VERSION "dbc-export 1 2026.26.6.5"

NS_ :

BS_:

BU_: APP BMS CC CMP CMPD CP DAS DI DIF DIR EPBL EPBR EVSE FC GTW HCML HCMR HVP ICR PCS PCS2 PLG PM PMF PMR PTC SCCM SCM SCS SDCR TAS UMC V2G VC VCBATT VCBATT0 VCBATT1 VCBATT2 VCFRONT VCFRONT1 VCFRONT2 VCLEFT VCRIGHT VCSEAT2L VCSEAT2R VCSEC

BO_ 798 CP_alertMatrix: 8 CP
 SG_ CP_matrixIndex M : 0|4@1+ (1,0) [0|15] "" Vector__XXX
 SG_ CP_a001_canRx m0 : 4|1@1+ (1,0) [0|1] "" Vector__XXX
 SG_ CP_a002_canTx m0 : 5|1@1+ (1,0) [0|1] "" Vector__XXX
 SG_ CP_a003_canError m0 : 6|1@1+ (1,0) [0|1] "" Vector__XXX
 SG_ CP_a004_proximityRationality m0 : 7|1@1+ (1,0) [0|1] "" Vector__XXX
 SG_ CP_a005_gbdcLiveDisconnect m0 : 8|1@1+ (1,0) [0|1] "" Vector__XXX
 SG_ CP_a006_lostCommsBMS m0 : 9|1@1+ (1,0) [0|1] "" Vector__XXX
 SG_ CP_a007_watchdog m0 : 10|1@1+ (1,0) [0|1] "" Vector__XXX
 SG_ CP_a008_memoryError m0 : 11|1@1+ (1,0) [0|1] "" Vector__XXX
 SG_ CP_a009_coverOpenAllChgBlocked m0 : 12|1@1+ (1,0) [0|1] "" Vector__XXX
 SG_ CP_a010_pilotRationality m0 : 13|1@1+ (1,0) [0|1] "" Vector__XXX
 SG_ CP_a011_eeprom m0 : 14|1@1+ (1,0) [0|1] "" Vector__XXX
 SG_ CP_a012_ledDriver m0 : 15|1@1+ (1,0) [0|1] "" Vector__XXX
 SG_ CP_a013_lostCommsGTW m0 : 16|1@1+ (1,0) [0|1] "" Vector__XXX
 SG_ CP_a014_lostCommsCHG m0 : 17|1@1+ (1,0) [0|1] "" Vector__XXX
 SG_ CP_a015_apsVov m0 : 18|1@1+ (1,0) [0|1] "" Vector__XXX
 SG_ CP_a016_apsVuv m0 : 19|1@1+ (1,0) [0|1] "" Vector__XXX
 SG_ CP_a017_fiveVov m0 : 20|1@1+ (1,0) [0|1] "" Vector__XXX
 SG_ CP_a018_fiveVuv m0 : 21|1@1+ (1,0) [0|1] "" Vector__XXX
 SG_ CP_a019_threeVov m0 : 22|1@1+ (1,0) [0|1] "" Vector__XXX
 SG_ CP_a020_threeVuv m0 : 23|1@1+ (1,0) [0|1] "" Vector__XXX
 SG_ CP_a021_zeroVov m0 : 24|1@1+ (1,0) [0|1] "" Vector__XXX
 SG_ CP_a022_zeroVuv m0 : 25|1@1+ (1,0) [0|1] "" Vector__XXX
 SG_ CP_a023_gbdcSessionFailed m0 : 26|1@1+ (1,0) [0|1] "" Vector__XXX
 SG_ CP_a024_ledsUC m0 : 27|1@1+ (1,0) [0|1] "" Vector__XXX
 SG_ CP_a025_ledsOC m0 : 28|1@1+ (1,0) [0|1] "" Vector__XXX
 SG_ CP_a026_networkManagement m0 : 29|1@1+ (1,0) [0|1] "" Vector__XXX
 SG_ CP_a027_doorSensorOutOfSpec m0 : 30|1@1+ (1,0) [0|1] "" Vector__XXX
 SG_ CP_a028_insertEnableMismatch m0 : 31|1@1+ (1,0) [0|1] "" Vector__XXX
 SG_ CP_a029_doorClosedProxPilot m0 : 32|1@1+ (1,0) [0|1] "" Vector__XXX
 SG_ CP_a030_busOff m0 : 33|1@1+ (1,0) [0|1] "" Vector__XXX
 SG_ CP_a031_doorClosedCommandedOpen m0 : 34|1@1+ (1,0) [0|1] "" Vector__XXX
 SG_ CP_a032_doorOpenExpectedClosed m0 : 35|1@1+ (1,0) [0|1] "" Vector__XXX
 SG_ CP_a033_spiOpen m0 : 36|1@1+ (1,0) [0|1] "" Vector__XXX
 SG_ CP_a034_calibrationIncomplete m0 : 37|1@1+ (1,0) [0|1] "" Vector__XXX
 SG_ CP_a035_latchMovement_1 m0 : 38|1@1+ (1,0) [0|1] "" Vector__XXX
 SG_ CP_a036_latchNotDisengaged m0 : 39|1@1+ (1,0) [0|1] "" Vector__XXX
 SG_ CP_a037_latchNotEngaged m0 : 40|1@1+ (1,0) [0|1] "" Vector__XXX
 SG_ CP_a038_latchNotBlocking m0 : 41|1@1+ (1,0) [0|1] "" Vector__XXX
 SG_ CP_a039_latchMovement_2 m0 : 42|1@1+ (1,0) [0|1] "" Vector__XXX
 SG_ CP_a040_doNotUse m0 : 43|1@1+ (1,0) [0|1] "" Vector__XXX
 SG_ CP_a041_doorSensorUnplugged m0 : 44|1@1+ (1,0) [0|1] "" Vector__XXX
 SG_ CP_a042_doorAssemblyBroken m0 : 45|1@1+ (1,0) [0|1] "" Vector__XXX
 SG_ CP_a043_doorPotIrrational m0 : 46|1@1+ (1,0) [0|1] "" Vector__XXX
 SG_ CP_a044_lostCommsHVP m0 : 47|1@1+ (1,0) [0|1] "" Vector__XXX
 SG_ CP_a045_lostCommsVCSEC m0 : 48|1@1+ (1,0) [0|1] "" Vector__XXX
 SG_ CP_a046_lostCommsEVSE m0 : 49|1@1+ (1,0) [0|1] "" Vector__XXX
 SG_ CP_a047_lostCommsVCFRONT m0 : 50|1@1+ (1,0) [0|1] "" Vector__XXX
 SG_ CP_a048_lostCommsUI m0 : 51|1@1+ (1,0) [0|1] "" Vector__XXX
 SG_ CP_a049_multipleCablesDetected m0 : 52|1@1+ (1,0) [0|1] "" Vector__XXX
 SG_ CP_a050_latchNotConnected m0 : 53|1@1+ (1,0) [0|1] "" Vector__XXX
 SG_ CP_a051_doorInductiveSensorMIA m0 : 54|1@1+ (1,0) [0|1] "" Vector__XXX
 SG_ CP_a052_chademoNotSupported m0 : 55|1@1+ (1,0) [0|1] "" Vector__XXX
 SG_ CP_a053_proxLatchedNoPilot m0 : 56|1@1+ (1,0) [0|1] "" Vector__XXX
 SG_ CP_a054_cableNotSecured m0 : 57|1@1+ (1,0) [0|1] "" Vector__XXX
 SG_ CP_a055_chargeStoppedNoPilot m0 : 58|1@1+ (1,0) [0|1] "" Vector__XXX
 SG_ CP_a056_proxDisconnected m0 : 59|1@1+ (1,0) [0|1] "" Vector__XXX
 SG_ CP_a057_ccs1AdapterBtnPress m0 : 60|1@1+ (1,0) [0|1] "" Vector__XXX
 SG_ CP_a058_acChargeRetryPending m0 : 61|1@1+ (1,0) [0|1] "" Vector__XXX
 SG_ CP_a059_swcanError m0 : 62|1@1+ (1,0) [0|1] "" Vector__XXX
 SG_ CP_a060_lostCommsPCS m0 : 63|1@1+ (1,0) [0|1] "" Vector__XXX
 SG_ CP_a061_uhfReceiverMIA m1 : 4|1@1+ (1,0) [0|1] "" Vector__XXX
 SG_ CP_a062_scOutOfService m1 : 5|1@1+ (1,0) [0|1] "" Vector__XXX
 SG_ CP_a063_scUpdateInProgress m1 : 6|1@1+ (1,0) [0|1] "" Vector__XXX
 SG_ CP_a064_superchargingBlocked m1 : 7|1@1+ (1,0) [0|1] "" Vector__XXX
 SG_ CP_a065_selfTestFailed m1 : 8|1@1+ (1,0) [0|1] "" Vector__XXX
 SG_ CP_a066_proxLatchedIdlePilot m1 : 9|1@1+ (1,0) [0|1] "" Vector__XXX
 SG_ CP_a067_gbdcConnFault m1 : 10|1@1+ (1,0) [0|1] "" Vector__XXX
 SG_ CP_a068_doorSensorMismatch m1 : 11|1@1+ (1,0) [0|1] "" Vector__XXX
 SG_ CP_a069_doorInductiveSensorError m1 : 12|1@1+ (1,0) [0|1] "" Vector__XXX
 SG_ CP_a070_doorInductiveSensorReset m1 : 13|1@1+ (1,0) [0|1] "" Vector__XXX
 SG_ CP_a071_exiDecodeFailure m1 : 14|1@1+ (1,0) [0|1] "" Vector__XXX
 SG_ CP_a072_v2gEvccTimeout m1 : 15|1@1+ (1,0) [0|1] "" Vector__XXX
 SG_ CP_a073_iecComboShutdown m1 : 16|1@1+ (1,0) [0|1] "" Vector__XXX
 SG_ CP_a074_failedToEstablishV2gComm m1 : 17|1@1+ (1,0) [0|1] "" Vector__XXX
 SG_ CP_a075_v2gCommsFailure m1 : 18|1@1+ (1,0) [0|1] "" Vector__XXX
 SG_ CP_a076_LDC1612errorWatchdog m1 : 19|1@1+ (1,0) [0|1] "" Vector__XXX
 SG_ CP_a077_invalidMacAddress m1 : 20|1@1+ (1,0) [0|1] "" Vector__XXX
 SG_ CP_a078_latchNotDisengagedCold m1 : 21|1@1+ (1,0) [0|1] "" Vector__XXX
 SG_ CP_a079_cableNotSecuredCold m1 : 22|1@1+ (1,0) [0|1] "" Vector__XXX
 SG_ CP_a080_taskStackOverflow m1 : 23|1@1+ (1,0) [0|1] "" Vector__XXX
 SG_ CP_a081_swException m1 : 24|1@1+ (1,0) [0|1] "" Vector__XXX
 SG_ CP_a082_powerOnReset m1 : 25|1@1+ (1,0) [0|1] "" Vector__XXX
 SG_ CP_a083_watchdogTraceData m1 : 26|1@1+ (1,0) [0|1] "" Vector__XXX
 SG_ CP_a084_proxPeDisconnected_gb m1 : 27|1@1+ (1,0) [0|1] "" Vector__XXX
 SG_ CP_a085_dcPinTempFaulted m1 : 28|1@1+ (1,0) [0|1] "" Vector__XXX
 SG_ CP_a086_dcPinTempIrrational m1 : 29|1@1+ (1,0) [0|1] "" Vector__XXX
 SG_ CP_a087_dcTempModelFault m1 : 30|1@1+ (1,0) [0|1] "" Vector__XXX
 SG_ CP_a088_dcTempModelDeviation m1 : 31|1@1+ (1,0) [0|1] "" Vector__XXX
 SG_ CP_a089_plcConfigMismatch m1 : 32|1@1+ (1,0) [0|1] "" Vector__XXX
 SG_ CP_a090_ccsEvseLowIso m1 : 33|1@1+ (1,0) [0|1] "" Vector__XXX
 SG_ CP_a091_wrongSuperchargerHandle m1 : 34|1@1+ (1,0) [0|1] "" Vector__XXX
 SG_ CP_a092_modemAppLoadFailed m1 : 35|1@1+ (1,0) [0|1] "" Vector__XXX
 SG_ CP_a093_modemLoadedWithReset m1 : 36|1@1+ (1,0) [0|1] "" Vector__XXX
 SG_ CP_a094_inductiveResetSuccessful m1 : 37|1@1+ (1,0) [0|1] "" Vector__XXX
 SG_ CP_a095_thermalDcLimitActive m1 : 38|1@1+ (1,0) [0|1] "" Vector__XXX
 SG_ CP_a096_pilotWake m1 : 39|1@1+ (1,0) [0|1] "" Vector__XXX
 SG_ CP_a097_modeTransitionFailure m1 : 40|1@1+ (1,0) [0|1] "" Vector__XXX
 SG_ CP_a098_proximityWake m1 : 41|1@1+ (1,0) [0|1] "" Vector__XXX
 SG_ CP_a099_cableStateUnknown m1 : 42|1@1+ (1,0) [0|1] "" Vector__XXX
 SG_ CP_a100_inletHarnessIdIrrational m1 : 43|1@1+ (1,0) [0|1] "" Vector__XXX
 SG_ CP_a101_wcFoldbackActive m1 : 44|1@1+ (1,0) [0|1] "" Vector__XXX
 SG_ CP_a102_wcOvertempFault m1 : 45|1@1+ (1,0) [0|1] "" Vector__XXX
 SG_ CP_a103_proximityPeDisconnected m1 : 46|1@1+ (1,0) [0|1] "" Vector__XXX
 SG_ CP_a104_uhfResetSuccessful m1 : 47|1@1+ (1,0) [0|1] "" Vector__XXX
 SG_ CP_a105_hwUnableToSleep m1 : 48|1@1+ (1,0) [0|1] "" Vector__XXX
 SG_ CP_a106_uhfReceiverReset m1 : 49|1@1+ (1,0) [0|1] "" Vector__XXX
 SG_ CP_a107_chademoFoldbackActive m1 : 50|1@1+ (1,0) [0|1] "" Vector__XXX
 SG_ CP_a108_chademoOvertempFault m1 : 51|1@1+ (1,0) [0|1] "" Vector__XXX
 SG_ CP_a109_thermistorIrrational m1 : 52|1@1+ (1,0) [0|1] "" Vector__XXX
 SG_ CP_a110_thermalVelocityHigh m1 : 53|1@1+ (1,0) [0|1] "" Vector__XXX
 SG_ CP_a111_inletHeaterUnableToHeat m1 : 54|1@1+ (1,0) [0|1] "" Vector__XXX
 SG_ CP_a112_inletHeaterIrrationalTem m1 : 55|1@1+ (1,0) [0|1] "" Vector__XXX
 SG_ CP_a113_inletHeaterShortCircuit m1 : 56|1@1+ (1,0) [0|1] "" Vector__XXX
 SG_ CP_a114_ccsEvseFailed m1 : 57|1@1+ (1,0) [0|1] "" Vector__XXX
 SG_ CP_a115_unexpectedTcan1145State m1 : 58|1@1+ (1,0) [0|1] "" Vector__XXX
 SG_ CP_a116_misconfigurationDetected m1 : 59|1@1+ (1,0) [0|1] "" Vector__XXX
 SG_ CP_a117_inletHeaterUnableToRegul m1 : 60|1@1+ (1,0) [0|1] "" Vector__XXX
 SG_ CP_a118_iecComboLockUp m1 : 61|1@1+ (1,0) [0|1] "" Vector__XXX
 SG_ CP_a119_plcTransmitFailure m1 : 62|1@1+ (1,0) [0|1] "" Vector__XXX
 SG_ CP_a120_comboAdapterFoldback m1 : 63|1@1+ (1,0) [0|1] "" Vector__XXX
 SG_ CP_a121_PLCRLY_lostCommsCP m2 : 4|1@1+ (1,0) [0|1] "" Vector__XXX
 SG_ CP_a122_plcModemFailure m2 : 5|1@1+ (1,0) [0|1] "" Vector__XXX
 SG_ CP_a123_latchPotIrrational m2 : 6|1@1+ (1,0) [0|1] "" Vector__XXX
 SG_ CP_a124_ivledFault m2 : 7|1@1+ (1,0) [0|1] "" Vector__XXX
 SG_ CP_a125_unexpectedLVJuiceState m2 : 8|1@1+ (1,0) [0|1] "" Vector__XXX
 SG_ CP_a126_wakeOnUhfFault m2 : 9|1@1+ (1,0) [0|1] "" Vector__XXX
 SG_ CP_a127_lostCommsHVLINK m2 : 10|1@1+ (1,0) [0|1] "" Vector__XXX
 SG_ CP_a128_lostCommsVC m2 : 11|1@1+ (1,0) [0|1] "" Vector__XXX
 SG_ CP_a129_bldcDriverCommsFailed m2 : 12|1@1+ (1,0) [0|1] "" Vector__XXX
 SG_ CP_a130_bldcDriverCommsRecovered m2 : 13|1@1+ (1,0) [0|1] "" Vector__XXX
 SG_ CP_a131_evseCommTimeout m2 : 14|1@1+ (1,0) [0|1] "" Vector__XXX
 SG_ CP_a132_contractAuthTimeout m2 : 15|1@1+ (1,0) [0|1] "" Vector__XXX
 SG_ CP_a133_proxNeverLatched m2 : 16|1@1+ (1,0) [0|1] "" Vector__XXX
 SG_ CP_a134_plcModemNotExpected m2 : 17|1@1+ (1,0) [0|1] "" Vector__XXX
 SG_ CP_a135_sdpAttemptsFailed m2 : 18|1@1+ (1,0) [0|1] "" Vector__XXX
 SG_ CP_a136_sdpSideReqFailed m2 : 19|1@1+ (1,0) [0|1] "" Vector__XXX
 SG_ CP_a137_plcForwardError m2 : 20|1@1+ (1,0) [0|1] "" Vector__XXX
 SG_ CP_a138_swcanCommsAcEvseFaulted m2 : 21|1@1+ (1,0) [0|1] "" Vector__XXX
 SG_ CP_a139_pilotFaulted m2 : 22|1@1+ (1,0) [0|1] "" Vector__XXX
 SG_ CP_a140_superchargerFaulted m2 : 23|1@1+ (1,0) [0|1] "" Vector__XXX
 SG_ CP_a141_chademoAdapterFault m2 : 24|1@1+ (1,0) [0|1] "" Vector__XXX
 SG_ CP_a142_gbdcScConnFault m2 : 25|1@1+ (1,0) [0|1] "" Vector__XXX
 SG_ CP_a143_unsupportedChargeAdapter m2 : 26|1@1+ (1,0) [0|1] "" Vector__XXX
 SG_ CP_a144_nvmInitFailed m2 : 27|1@1+ (1,0) [0|1] "" Vector__XXX
 SG_ CP_a145_modemAppLoadFailedNA m2 : 28|1@1+ (1,0) [0|1] "" Vector__XXX
 SG_ CP_a146_ccsEvseMalfunction m2 : 29|1@1+ (1,0) [0|1] "" Vector__XXX
 SG_ CP_a147_inductiveRecoveredMia m2 : 30|1@1+ (1,0) [0|1] "" Vector__XXX
 SG_ CP_a148_bldcTachFeedbackMia m2 : 31|1@1+ (1,0) [0|1] "" Vector__XXX
 SG_ CP_a149_pilotPeriodInvalid m2 : 32|1@1+ (1,0) [0|1] "" Vector__XXX
 SG_ CP_a150_railToggleTimeout m2 : 33|1@1+ (1,0) [0|1] "" Vector__XXX
 SG_ CP_a151_badPilotDiodeDetected m2 : 34|1@1+ (1,0) [0|1] "" Vector__XXX
 SG_ CP_a152_pilotEdgeDetectionFailed m2 : 35|1@1+ (1,0) [0|1] "" Vector__XXX
 SG_ CP_a153_thermalAcLimitActive m2 : 36|1@1+ (1,0) [0|1] "" Vector__XXX
 SG_ CP_a154_acChargingStoppedOT m2 : 37|1@1+ (1,0) [0|1] "" Vector__XXX
 SG_ CP_a155_hallPresenceRationality m2 : 38|1@1+ (1,0) [0|1] "" Vector__XXX
 SG_ CP_a156_gbdcPrechargingConcern m2 : 39|1@1+ (1,0) [0|1] "" Vector__XXX
 SG_ CP_a157_doorOpenRateLimiter m2 : 40|1@1+ (1,0) [0|1] "" Vector__XXX
 SG_ CP_a158_doorCloseRateLimiter m2 : 41|1@1+ (1,0) [0|1] "" Vector__XXX
 SG_ CP_a159_swcanHealthCheckFailed m2 : 42|1@1+ (1,0) [0|1] "" Vector__XXX
 SG_ CP_a160_latchDisengageInDcCharge m2 : 43|1@1+ (1,0) [0|1] "" Vector__XXX
 SG_ CP_a161_badPilotDiodeDetectedCN m2 : 44|1@1+ (1,0) [0|1] "" Vector__XXX
 SG_ CP_a162_pilotEdgeDetectionFailed m2 : 45|1@1+ (1,0) [0|1] "" Vector__XXX
 SG_ CP_a163_coverOpenDcChgBlocked m2 : 46|1@1+ (1,0) [0|1] "" Vector__XXX
 SG_ CP_a164_latchRedisengageRequeste m2 : 47|1@1+ (1,0) [0|1] "" Vector__XXX
 SG_ CP_a165_proxWiggleDetected m2 : 48|1@1+ (1,0) [0|1] "" Vector__XXX
 SG_ CP_a166_faultLineMismatchDetecte m2 : 49|1@1+ (1,0) [0|1] "" Vector__XXX
 SG_ CP_a167_doorIdIrrational m2 : 50|1@1+ (1,0) [0|1] "" Vector__XXX
 SG_ CP_a168_pilotHSDFaulted m2 : 51|1@1+ (1,0) [0|1] "" Vector__XXX
 SG_ CP_a170_selfTestFailed2 m2 : 53|1@1+ (1,0) [0|1] "" Vector__XXX
 SG_ CP_a172_triggerOdin m2 : 55|1@1+ (1,0) [0|1] "" Vector__XXX
 SG_ CP_a173_coverOpenAcChgBlocked m2 : 56|1@1+ (1,0) [0|1] "" Vector__XXX
 SG_ CP_a174_fwdedMsgLoadWarning m2 : 57|1@1+ (1,0) [0|1] "" Vector__XXX
 SG_ CP_a175_fwdedMsgDropped m2 : 58|1@1+ (1,0) [0|1] "" Vector__XXX
 SG_ CP_a176_lostCommsV2l m2 : 59|1@1+ (1,0) [0|1] "" Vector__XXX
 SG_ CP_a177_incompatibleV2lDeviceDet m2 : 60|1@1+ (1,0) [0|1] "" Vector__XXX
 SG_ CP_a178_v2xPlcCommsFault m2 : 61|1@1+ (1,0) [0|1] "" Vector__XXX
 SG_ CP_a179_evseCommsTlsError m2 : 62|1@1+ (1,0) [0|1] "" Vector__XXX
 SG_ CP_a182_pncdCommsError m3 : 5|1@1+ (1,0) [0|1] "" Vector__XXX
 SG_ CP_a183_certManagerError m3 : 6|1@1+ (1,0) [0|1] "" Vector__XXX
 SG_ CP_a184_certChangeEvent m3 : 7|1@1+ (1,0) [0|1] "" Vector__XXX
 SG_ CP_a185_pncAuthRejection m3 : 8|1@1+ (1,0) [0|1] "" Vector__XXX
 SG_ CP_a186_spiDmaFailure m3 : 9|1@1+ (1,0) [0|1] "" Vector__XXX
 SG_ CP_a187_highStackUsage m3 : 10|1@1+ (1,0) [0|1] "" Vector__XXX
 SG_ CP_a188_v2lEvseRequiresUpdate m3 : 11|1@1+ (1,0) [0|1] "" Vector__XXX
 SG_ CP_a189_resistivePresenceRationa m3 : 12|1@1+ (1,0) [0|1] "" Vector__XXX
 SG_ CP_d190_backCoverCircuitIssue m3 : 13|1@1+ (1,0) [0|1] "" Vector__XXX
 SG_ CP_d191_latchConnectionIssue m3 : 14|1@1+ (1,0) [0|1] "" Vector__XXX
 SG_ CP_d192_couplerTempHigh m3 : 15|1@1+ (1,0) [0|1] "" Vector__XXX
 SG_ CP_d193_proximityCircuitErratic m3 : 16|1@1+ (1,0) [0|1] "" Vector__XXX
 SG_ CP_d194_proximityCircuitRangeIss m3 : 17|1@1+ (1,0) [0|1] "" Vector__XXX
 SG_ CP_d195_couplerLockActuatorIssue m3 : 18|1@1+ (1,0) [0|1] "" Vector__XXX
 SG_ CP_d196_doorActuatorPerformanceI m3 : 19|1@1+ (1,0) [0|1] "" Vector__XXX
 SG_ CP_d197_doorSensorCircuitErratic m3 : 20|1@1+ (1,0) [0|1] "" Vector__XXX
 SG_ CP_d198_couplerTempSensorCircuit m3 : 21|1@1+ (1,0) [0|1] "" Vector__XXX
 SG_ CP_d199_hardwareConfigMismatch m3 : 22|1@1+ (1,0) [0|1] "" Vector__XXX
 SG_ CP_d200_pilotCircuitIssue m3 : 23|1@1+ (1,0) [0|1] "" Vector__XXX
 SG_ CP_a201_uhfDoorOpenRepeatedlyOve m3 : 24|1@1+ (1,0) [0|1] "" Vector__XXX
 SG_ CP_a202_failedToEstablishV2gComm m3 : 25|1@1+ (1,0) [0|1] "" Vector__XXX
 SG_ CP_a203_evseCommTimeout2 m3 : 26|1@1+ (1,0) [0|1] "" Vector__XXX
 SG_ CP_a204_sdpAttemptsFailed2 m3 : 27|1@1+ (1,0) [0|1] "" Vector__XXX
 SG_ CP_a205_doorPositionUndetectable m3 : 28|1@1+ (1,0) [0|1] "" Vector__XXX
 SG_ CP_a206_peToChassisDisconnected m3 : 29|1@1+ (1,0) [0|1] "" Vector__XXX
 SG_ CP_a207_v2xAuthenticationFailed m3 : 30|1@1+ (1,0) [0|1] "" Vector__XXX
 SG_ CP_a208_eipmCommsError m3 : 31|1@1+ (1,0) [0|1] "" Vector__XXX
 SG_ CP_a209_macphyFault m3 : 32|1@1+ (1,0) [0|1] "" Vector__XXX
 SG_ CP_a210_lostCommsPCSR m3 : 33|1@1+ (1,0) [0|1] "" Vector__XXX
 SG_ CP_a211_lostCommsPCSL m3 : 34|1@1+ (1,0) [0|1] "" Vector__XXX
 SG_ CP_a212_mcsPacketDrops m3 : 35|1@1+ (1,0) [0|1] "" Vector__XXX
 SG_ CP_a213_mcsTcpRetransmitStorm m3 : 36|1@1+ (1,0) [0|1] "" Vector__XXX
 SG_ CP_a214_mcsEthDriverRetransmitFa m3 : 37|1@1+ (1,0) [0|1] "" Vector__XXX
 SG_ CP_a215_mcsMacPhyErrors m3 : 38|1@1+ (1,0) [0|1] "" Vector__XXX
 SG_ CP_a216_mcsLinkLoss m3 : 39|1@1+ (1,0) [0|1] "" Vector__XXX
 SG_ CP_a217_teslaV2gCommsFailure m3 : 40|1@1+ (1,0) [0|1] "" Vector__XXX
 SG_ CP_a218_v2gCommsFailure2 m3 : 41|1@1+ (1,0) [0|1] "" Vector__XXX
 SG_ CP_a219_doorOpenInDrive m3 : 42|1@1+ (1,0) [0|1] "" Vector__XXX
 SG_ CP_a220_mcsChargingInterrupted m3 : 43|1@1+ (1,0) [0|1] "" Vector__XXX
 SG_ CP_a221_evseStartupTimeout m3 : 44|1@1+ (1,0) [0|1] "" Vector__XXX

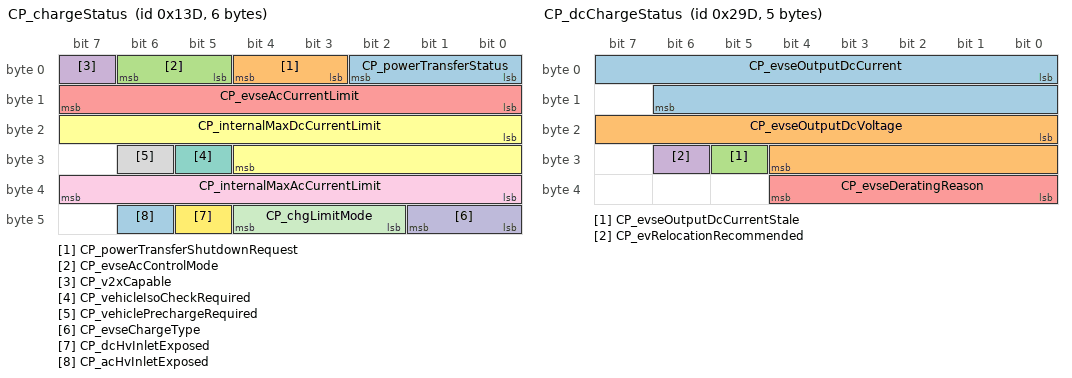
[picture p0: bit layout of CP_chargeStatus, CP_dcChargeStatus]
BO_ 317 CP_chargeStatus: 6 CP
 SG_ CP_powerTransferStatus : 0|3@1+ (1,0) [0|7] "" Vector__XXX
 SG_ CP_powerTransferShutdownRequest : 3|2@1+ (1,0) [0|3] "" Vector__XXX
 SG_ CP_evseAcControlMode : 5|2@1+ (1,0) [0|3] "" Vector__XXX
 SG_ CP_v2xCapable : 7|1@1+ (1,0) [0|1] "" Vector__XXX
 SG_ CP_evseAcCurrentLimit : 8|8@1+ (0.5,0) [0|127.5] "A" Vector__XXX
 SG_ CP_internalMaxDcCurrentLimit : 16|13@1+ (0.25,0) [0|2047.75] "A" Vector__XXX
 SG_ CP_vehicleIsoCheckRequired : 29|1@1+ (1,0) [0|1] "" Vector__XXX
 SG_ CP_vehiclePrechargeRequired : 30|1@1+ (1,0) [0|1] "" Vector__XXX
 SG_ CP_internalMaxAcCurrentLimit : 32|8@1+ (0.5,0) [0|127.5] "A" Vector__XXX
 SG_ CP_evseChargeType : 40|2@1+ (1,0) [0|3] "" Vector__XXX
 SG_ CP_chgLimitMode : 42|3@1+ (1,0) [0|7] "" Vector__XXX
 SG_ CP_dcHvInletExposed : 45|1@1+ (1,0) [0|1] "" Vector__XXX
 SG_ CP_acHvInletExposed : 46|1@1+ (1,0) [0|1] "" Vector__XXX

BO_ 669 CP_dcChargeStatus: 5 CP
 SG_ CP_evseOutputDcCurrent : 0|15@1- (0.125,0) [-2048|2047.875] "A" Vector__XXX
 SG_ CP_evseOutputDcVoltage : 16|13@1+ (0.07324219,0) [0|599.92675822] "V" Vector__XXX
 SG_ CP_evseOutputDcCurrentStale : 29|1@1+ (1,0) [0|1] "" Vector__XXX
 SG_ CP_evRelocationRecommended : 30|1@1+ (1,0) [0|1] "" Vector__XXX
 SG_ CP_evseDeratingReason : 32|5@1+ (1,0) [0|31] "" Vector__XXX

BO_ 541 CP_evseStatus: 8 CP
 SG_ CP_evseAccept : 0|1@1+ (1,0) [0|1] "" Vector__XXX
 SG_ CP_evseRequest : 1|1@1+ (1,0) [0|1] "" Vector__XXX
 SG_ CP_proximity : 2|2@1+ (1,0) [1|3] "" Vector__XXX
 SG_ CP_pilot : 4|3@1+ (1,0) [0|6] "" Vector__XXX
 SG_ CP_digitalCommsEstablished : 7|1@1+ (1,0) [0|1] "" Vector__XXX
 SG_ CP_pilotCurrent : 8|8@1+ (0.5,0) [0|127.5] "A" Vector__XXX
 SG_ CP_cableType : 16|3@1+ (1,0) [0|7] "" Vector__XXX
 SG_ CP_iecPilotState : 19|4@1+ (1,0) [0|15] "" Vector__XXX
 SG_ CP_plcSupported : 23|1@1+ (1,0) [0|1] "" Vector__XXX
 SG_ CP_cableCurrentLimit : 24|7@1+ (1,0) [0|127] "A" Vector__XXX
 SG_ CP_teslaSwcanState : 34|4@1+ (1,0) [0|15] "" Vector__XXX
 SG_ CP_evseChargeType_UI : 38|2@1+ (1,0) [0|3] "" Vector__XXX
 SG_ CP_gbState : 40|4@1+ (1,0) [0|15] "" Vector__XXX
 SG_ CP_gbdcStopChargeReason : 44|4@1+ (1,0) [0|15] "" Vector__XXX
 SG_ CP_gbdcFailureReason : 48|2@1+ (1,0) [0|3] "" Vector__XXX
 SG_ CP_gbdcChargeAttempts : 50|2@1+ (1,0) [0|3] "" Vector__XXX
 SG_ CP_acChargeState : 52|3@1+ (1,0) [0|7] "" Vector__XXX
 SG_ CP_acChargeType : 56|2@1+ (1,0) [0|3] "" Vector__XXX
 SG_ CP_teslaDcState : 58|4@1+ (1,0) [0|15] "" Vector__XXX

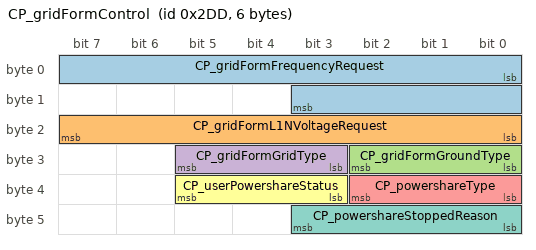
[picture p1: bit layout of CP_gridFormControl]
BO_ 733 CP_gridFormControl: 6 CP
 SG_ CP_gridFormFrequencyRequest : 0|12@1+ (0.01,40) [40|80.94] "Hz" Vector__XXX
 SG_ CP_gridFormL1NVoltageRequest : 16|8@1+ (1,40) [40|294] "V" Vector__XXX
 SG_ CP_gridFormGroundType : 24|3@1+ (1,0) [1|7] "" Vector__XXX
 SG_ CP_gridFormGridType : 27|3@1+ (1,0) [1|7] "" Vector__XXX
 SG_ CP_powershareType : 32|3@1+ (1,0) [0|7] "" Vector__XXX
 SG_ CP_userPowershareStatus : 35|3@1+ (1,0) [0|7] "" Vector__XXX
 SG_ CP_powershareStoppedReason : 40|4@1+ (1,0) [0|15] "" Vector__XXX

BO_ 1342 CP_info: 8 CP
 SG_ CP_infoIndex M : 0|8@1+ (1,0) [0|255] "" Vector__XXX
 SG_ CP_buildType m10 : 8|3@1+ (1,0) [0|7] "" Vector__XXX
 SG_ CP_buildConfigId m10 : 16|16@1+ (1,0) [0|65535] "" Vector__XXX
 SG_ CP_hardwareId m10 : 32|16@1+ (1,0) [0|65535] "" Vector__XXX
 SG_ CP_componentId m10 : 48|16@1+ (1,0) [0|65535] "" Vector__XXX
 SG_ CP_pcbaId m11 : 16|8@1+ (1,0) [0|255] "" Vector__XXX
 SG_ CP_assemblyId m11 : 24|8@1+ (1,0) [0|255] "" Vector__XXX
 SG_ CP_usageId m11 : 32|16@1+ (1,0) [0|65535] "" Vector__XXX
 SG_ CP_subUsageId m11 : 48|16@1+ (1,0) [0|65535] "" Vector__XXX
 SG_ CP_platformType m13 : 8|8@1+ (1,0) [0|255] "" Vector__XXX
 SG_ CP_appCrc m13 : 32|32@1+ (1,0) [0|4294967295] "" Vector__XXX
 SG_ CP_appGitHash m17 : 8|56@1+ (1,0) [0|7.20575940379e+16] "" Vector__XXX
 SG_ CP_bootGitHash m18 : 8|56@1+ (1,0) [0|7.20575940379e+16] "" Vector__XXX
 SG_ CP_bootUdsProtoVersion m20 : 8|8@1+ (1,0) [0|255] "" Vector__XXX
 SG_ CP_bootCrc m20 : 32|32@1+ (1,0) [0|4294967295] "" Vector__XXX

BO_ 1885 CP_loggingFast: 8 CP
 SG_ CP_loggingFastSelect M : 0|4@1+ (1,0) [0|15] "" Vector__XXX
 SG_ CP_inductiveSensor_raw m0 : 4|28@1+ (1,0) [0|268435455] "" Vector__XXX
 SG_ CP_doorOpenActuationTime m0 : 32|14@1+ (1,0) [0|16383] "ms" Vector__XXX
 SG_ CP_doorCloseActuationTime m0 : 46|14@1+ (1,0) [0|16383] "ms" Vector__XXX
 SG_ CP_chargeCableSecured m0 : 60|1@1+ (1,0) [0|1] "" Vector__XXX
 SG_ CP_chargeCablePresent m0 : 61|1@1+ (1,0) [0|1] "" Vector__XXX
 SG_ CP_latchCheckAvailable m0 : 62|1@1+ (1,0) [0|1] "" Vector__XXX
 SG_ CP_UHF_controlState m2 : 4|4@1+ (1,0) [0|15] "" Vector__XXX
 SG_ CP_proximityV m2 : 8|16@1+ (0.0001,0) [0|6.5535] "V" Vector__XXX
 SG_ CP_proximityV_GBCC1 m2 : 24|14@1+ (0.001,0) [0|13.3] "V" Vector__XXX
 SG_ CP_proximityV_GBCC2 m2 : 38|14@1+ (0.001,0) [0|13.3] "V" Vector__XXX
 SG_ CP_doorPot m2 : 52|12@1+ (0.025,0) [0|100] "%" Vector__XXX
 SG_ CP_doorPresenceSensorV m3 : 4|12@1+ (0.001221,0) [0|4.999995] "V" Vector__XXX
 SG_ CP_doorOpenRequest m3 : 16|4@1+ (1,0) [0|15] "" Vector__XXX
 SG_ CP_doorOpenEndOfDriveReason m3 : 20|3@1+ (1,0) [0|7] "" Vector__XXX
 SG_ CP_coverClosed m3 : 23|1@1+ (1,0) [0|1] "" Vector__XXX
 SG_ CP_doorCloseEndOfDriveReason m3 : 24|3@1+ (1,0) [0|7] "" Vector__XXX
 SG_ CP_doorCloseRequest m3 : 27|5@1+ (1,0) [0|31] "" Vector__XXX
 SG_ CP_latchDisengagingTime m3 : 32|10@1+ (1,0) [0|1023] "ms" Vector__XXX
 SG_ CP_latchEngagingTime m3 : 42|10@1+ (1,0) [0|1023] "ms" Vector__XXX
 SG_ CP_latchDisengagingStopReason m3 : 52|3@1+ (1,0) [0|7] "" Vector__XXX
 SG_ CP_latchEngagingStopReason m3 : 55|3@1+ (1,0) [0|7] "" Vector__XXX
 SG_ CP_pilotUnlatchRequestActive m3 : 58|1@1+ (1,0) [0|1] "" Vector__XXX
 SG_ CP_doorIdDetectionState m3 : 59|2@1+ (1,0) [1|3] "" Vector__XXX
 SG_ CP_doorIdDetectedBin m3 : 61|2@1+ (1,0) [0|3] "" Vector__XXX
 SG_ CP_semiV2LatchNonLinear m3 : 63|1@1+ (1,0) [0|1] "" Vector__XXX

BO_ 989 CP_loggingSlow: 8 CP
 SG_ CP_loggingSlowSelect M : 0|4@1+ (1,0) [0|15] "" Vector__XXX
 SG_ CP_UHF_chipState m3 : 4|3@1+ (1,0) [0|7] "" Vector__XXX
 SG_ CP_UHF_rssi m3 : 8|8@1+ (1,0) [0|255] "" Vector__XXX
 SG_ CP_UHF_rxOverflow m3 : 16|1@1+ (1,0) [0|1] "" Vector__XXX
 SG_ CP_UHF_rxNumBytes m3 : 17|8@1+ (1,0) [0|255] "" Vector__XXX
 SG_ CP_UHF_selfTestRssi m3 : 25|8@1+ (1,0) [0|255] "" Vector__XXX
 SG_ CP_latchI m3 : 33|12@1+ (0.0025,0) [0|10.2375] "A" Vector__XXX
 SG_ CP_inlet1HarnessIdState m3 : 45|2@1+ (1,0) [1|3] "" Vector__XXX
 SG_ CP_inlet1HarnessIdValue m3 : 47|3@1+ (1,0) [0|7] "" Vector__XXX
 SG_ CP_inlet2HarnessIdState m3 : 50|2@1+ (1,0) [1|3] "" Vector__XXX
 SG_ CP_inlet2HarnessIdValue m3 : 52|3@1+ (1,0) [0|7] "" Vector__XXX
 SG_ CP_inletHeaterState m3 : 55|2@1+ (1,0) [0|3] "" Vector__XXX
 SG_ CP_inletHeaterDuty m3 : 57|7@1+ (1,0) [0|100] "%" Vector__XXX
 SG_ CP_5vSwV m4 : 4|8@1+ (0.02745098,0) [0|6.9999999] "V" Vector__XXX
 SG_ CP_boardTemperature m4 : 12|8@1+ (1.29411768913,-50) [-50|280] "C" Vector__XXX
 SG_ CP_refVoltage m4 : 20|8@1+ (0.0070588234812,0) [0|1.79999998771] "V" Vector__XXX
 SG_ CP_doorId_intervalMin10s m4 : 28|8@1+ (0.0196078438312,0) [0|5] "V" Vector__XXX
 SG_ CP_doorId_intervalMax10s m4 : 36|8@1+ (0.0196078438312,0) [0|5] "V" Vector__XXX
 SG_ CP_wakeOnPushCounter m4 : 60|3@1+ (1,0) [0|7] "" Vector__XXX
 SG_ CP_doorPushLockoutActive m4 : 63|1@1+ (1,0) [0|1] "" Vector__XXX
 SG_ CP_nvm_dataValid m5 : 4|1@1+ (1,0) [0|1] "" Vector__XXX
 SG_ CP_nvm_doorOpenCycles m5 : 5|16@1+ (1,0) [0|65535] "" Vector__XXX
 SG_ CP_nvm_doorCloseCycles m5 : 21|16@1+ (1,0) [0|65535] "" Vector__XXX
 SG_ CP_nvm_doorOpen m5 : 37|1@1+ (1,0) [0|1] "" Vector__XXX
 SG_ CP_nvm_doorPresent m5 : 38|1@1+ (1,0) [0|1] "" Vector__XXX
 SG_ CP_nvm_doorPresentValid m5 : 39|1@1+ (1,0) [0|1] "" Vector__XXX
 SG_ CP_nvm_badPilotDiodeDetected m5 : 40|1@1+ (1,0) [0|1] "" Vector__XXX
 SG_ CP_nvm_pilotDiodeFaultCount m5 : 41|3@1+ (1,0) [0|7] "" Vector__XXX
 SG_ CP_doorOpenLimiterMaxCount m5 : 44|4@1+ (1,0) [0|15] "counts" Vector__XXX
 SG_ CP_doorOpenLimiterMaxRequestType m5 : 48|4@1+ (1,0) [0|15] "" Vector__XXX
 SG_ CP_doorCloseLimiterMaxCount m5 : 52|4@1+ (1,0) [0|15] "counts" Vector__XXX
 SG_ CP_doorCloseLimiterMaxRequestTyp m5 : 56|5@1+ (1,0) [0|31] "" Vector__XXX
 SG_ CP_proximityWakeCounter m5 : 61|3@1+ (1,0) [0|7] "" Vector__XXX

BO_ 605 CP_status: 8 CP
 SG_ CP_type : 0|2@1+ (1,0) [0|3] "" Vector__XXX
 SG_ CP_insertEnableLine : 2|1@1+ (1,0) [0|1] "" Vector__XXX
 SG_ CP_latchState : 3|2@1+ (1,0) [1|3] "" Vector__XXX
 SG_ CP_permanentPowerRequest : 5|1@1+ (1,0) [0|1] "" Vector__XXX
 SG_ CP_chargeDoorOpen : 6|1@1+ (1,0) [0|1] "" Vector__XXX
 SG_ CP_doorControlState : 8|3@1+ (1,0) [0|7] "" Vector__XXX
 SG_ CP_doorButtonPressed : 11|1@1+ (1,0) [0|1] "" Vector__XXX
 SG_ CP_swcanRelayClosed : 12|1@1+ (1,0) [0|1] "" Vector__XXX
 SG_ CP_inhibitOta : 13|1@1+ (1,0) [0|1] "" Vector__XXX
 SG_ CP_chargeCableState : 14|2@1+ (1,0) [1|3] "" Vector__XXX
 SG_ CP_latchControlState : 16|3@1+ (1,0) [0|7] "" Vector__XXX
 SG_ CP_ledColor : 19|4@1+ (1,0) [0|15] "" Vector__XXX
 SG_ CP_UHF_handleFound : 23|1@1+ (1,0) [0|1] "" Vector__XXX
 SG_ CP_faultLineSensed : 24|1@1+ (1,0) [0|1] "" Vector__XXX
 SG_ CP_doorPresenceState : 25|3@1+ (1,0) [0|7] "" Vector__XXX
 SG_ CP_inductiveSensorState : 28|3@1+ (1,0) [0|7] "" Vector__XXX
 SG_ CP_chargeDoorOpenUI : 31|1@1+ (1,0) [0|1] "" Vector__XXX
 SG_ CP_vehicleUnlockRequest : 32|1@1+ (1,0) [0|1] "" Vector__XXX
 SG_ CP_coldWeatherMode : 33|1@1+ (1,0) [0|1] "" Vector__XXX
 SG_ CP_latchEngaged : 34|1@1+ (1,0) [0|1] "" Vector__XXX
 SG_ CP_inletHeaterUiState : 37|3@1+ (1,0) [0|7] "" Vector__XXX
 SG_ CP_userEvseModelType : 40|4@1+ (1,0) [0|15] "" Vector__XXX
 SG_ CP_evseGridFormHardwareType : 44|4@1+ (1,0) [0|14] "" Vector__XXX
 SG_ CP_faultLineV : 48|10@1+ (0.00455057667568,0) [0|4.65523993922] "V" Vector__XXX
 SG_ CP_faultLineSetByCP : 58|1@1+ (1,0) [0|1] "" Vector__XXX
 SG_ CP_AuthManagerState : 59|4@1+ (1,0) [0|15] "" Vector__XXX

BO_ 893 CP_thermalStatus: 8 CP
 SG_ CP_thermalStatusSelect M : 0|1@1+ (1,0) [0|1] "" Vector__XXX
 SG_ CP_pinTemperature1 m1 : 8|8@1+ (0.8039216,-55) [-55|149.99] "C" Vector__XXX
 SG_ CP_pinTemperature2 m1 : 16|8@1+ (0.8039216,-55) [-55|149.99] "C" Vector__XXX
 SG_ CP_pinTemperature3 m1 : 24|8@1+ (0.8039216,-55) [-55|149.99] "C" Vector__XXX
 SG_ CP_pinTemperature4 m1 : 32|8@1+ (0.8039216,-55) [-55|149.99] "C" Vector__XXX
 SG_ CP_pinTemp4Velocity m1 : 40|10@1- (0.15748,0) [-80.47228|80.3148] "C/min" Vector__XXX

BO_ 1566 CP_udsResponse: 8 CP
 SG_ CP_udsResponseData : 7|64@0+ (1,0) [0|1.84467440737e+19] "" Vector__XXX

BO_ 1001 DAS_bodyControls: 8 DAS
 SG_ DAS_headlightRequest : 0|2@1+ (1,0) [0|3] "" Vector__XXX
 SG_ DAS_hazardLightRequest : 2|2@1+ (1,0) [0|2] "" Vector__XXX
 SG_ DAS_wiperSpeed : 4|4@1+ (1,0) [0|15] "" Vector__XXX
 SG_ DAS_turnIndicatorRequest : 8|3@1+ (1,0) [0|7] "" Vector__XXX
 SG_ DAS_highLowBeamDecision : 11|2@1+ (1,0) [0|2] "" Vector__XXX
 SG_ DAS_heaterRequest : 13|2@1+ (1,0) [1|3] "" Vector__XXX
 SG_ DAS_highLowBeamOffReason : 15|3@1+ (1,0) [0|7] "" Vector__XXX
 SG_ DAS_forwardCamHeaterDutyCycle : 18|4@1+ (0.06666667,0) [0|1] "-" Vector__XXX
 SG_ DAS_dynamicBrakeLightRequest : 22|1@1+ (1,0) [0|1] "" Vector__XXX
 SG_ DAS_radarHeaterRequest : 23|1@1+ (1,0) [0|1] "" Vector__XXX
 SG_ DAS_ahlbOverride : 24|1@1+ (1,0) [0|1] "" Vector__XXX
 SG_ DAS_mirrorFoldRequest : 25|2@1+ (1,0) [0|2] "" Vector__XXX
 SG_ DAS_wiperWashRequest : 27|1@1+ (1,0) [0|1] "" Vector__XXX
 SG_ DAS_ulcConfirmationRequestActive : 28|1@1+ (1,0) [0|1] "" Vector__XXX
 SG_ DAS_overrideWiperSetting : 29|1@1+ (1,0) [0|1] "" Vector__XXX
 SG_ DAS_autoWiperState : 30|3@1+ (1,0) [0|7] "" Vector__XXX
 SG_ DAS_turnIndicatorRequestReason : 33|5@1+ (1,0) [0|31] "" Vector__XXX
 SG_ DAS_forwardRadarPowerRequest : 38|1@1+ (1,0) [0|1] "" Vector__XXX
 SG_ DAS_driverDomeLightRequest : 39|1@1+ (1,0) [0|1] "" Vector__XXX
 SG_ DAS_drivePowerStateRequest : 43|1@1+ (1,0) [0|1] "" Vector__XXX
 SG_ DAS_enableIcrDataCollection : 44|1@1+ (1,0) [0|1] "" Vector__XXX
 SG_ DAS_rPillarCamHeaterDutyCycle : 45|4@1+ (0.06666667,0) [0|1] "-" Vector__XXX
 SG_ DAS_adaptiveHighBeamIsFaulted : 49|1@1+ (1,0) [0|1] "" Vector__XXX
 SG_ DAS_restrictDoorReleaseLeft : 50|1@1+ (1,0) [0|1] "" Vector__XXX
 SG_ DAS_restrictDoorReleaseRight : 51|1@1+ (1,0) [0|1] "" Vector__XXX
 SG_ DAS_bodyControlsCounter : 52|4@1+ (1,0) [0|15] "" Vector__XXX
 SG_ DAS_bodyControlsChecksum : 56|8@1+ (1,0) [0|255] "" Vector__XXX

BO_TX_BU_ 798 : CP;
BO_TX_BU_ 317 : CP;
BO_TX_BU_ 669 : CP;
BO_TX_BU_ 541 : CP;
BO_TX_BU_ 733 : CP;
BO_TX_BU_ 1342 : CP;
BO_TX_BU_ 1885 : CP;
BO_TX_BU_ 989 : CP;
BO_TX_BU_ 605 : CP;
BO_TX_BU_ 893 : CP;
BO_TX_BU_ 1566 : CP;
BO_TX_BU_ 1001 : DAS;
CM_ BO_ 798 "Charge port controller message: alert matrix; frame length from the layout, not yet observed on a vehicle bus";
CM_ SG_ 798 CP_matrixIndex "Charge port controller: matrix index";
CM_ SG_ 798 CP_a001_canRx "Charge port controller: a001 can rx";
CM_ SG_ 798 CP_a002_canTx "Charge port controller: a002 can tx";
CM_ SG_ 798 CP_a003_canError "Charge port controller: a003 can error";
CM_ SG_ 798 CP_a004_proximityRationality "Charge port controller: a004 proximity rationality";
CM_ SG_ 798 CP_a005_gbdcLiveDisconnect "Charge port controller: a005 gbdc live disconnect";
CM_ SG_ 798 CP_a006_lostCommsBMS "Charge port controller: a006 lost comms BMS";
CM_ SG_ 798 CP_a007_watchdog "Charge port controller: a007 watchdog";
CM_ SG_ 798 CP_a008_memoryError "Charge port controller: a008 memory error";
CM_ SG_ 798 CP_a009_coverOpenAllChgBlocked "Charge port controller: a009 cover open all chg blocked";
CM_ SG_ 798 CP_a010_pilotRationality "Charge port controller: a010 pilot rationality";
CM_ SG_ 798 CP_a011_eeprom "Charge port controller: a011 eeprom";
CM_ SG_ 798 CP_a012_ledDriver "Charge port controller: a012 led driver";
CM_ SG_ 798 CP_a013_lostCommsGTW "Charge port controller: a013 lost comms GTW";
CM_ SG_ 798 CP_a014_lostCommsCHG "Charge port controller: a014 lost comms CHG";
CM_ SG_ 798 CP_a015_apsVov "Charge port controller: a015 aps vov";
CM_ SG_ 798 CP_a016_apsVuv "Charge port controller: a016 aps vuv";
CM_ SG_ 798 CP_a017_fiveVov "Charge port controller: a017 five vov";
CM_ SG_ 798 CP_a018_fiveVuv "Charge port controller: a018 five vuv";
CM_ SG_ 798 CP_a019_threeVov "Charge port controller: a019 three vov";
CM_ SG_ 798 CP_a020_threeVuv "Charge port controller: a020 three vuv";
CM_ SG_ 798 CP_a021_zeroVov "Charge port controller: a021 zero vov";
CM_ SG_ 798 CP_a022_zeroVuv "Charge port controller: a022 zero vuv";
CM_ SG_ 798 CP_a023_gbdcSessionFailed "Charge port controller: a023 gbdc session failed";
CM_ SG_ 798 CP_a024_ledsUC "Charge port controller: a024 leds UC";
CM_ SG_ 798 CP_a025_ledsOC "Charge port controller: a025 leds OC";
CM_ SG_ 798 CP_a026_networkManagement "Charge port controller: a026 network management";
CM_ SG_ 798 CP_a027_doorSensorOutOfSpec "Charge port controller: a027 door sensor out of spec";
CM_ SG_ 798 CP_a028_insertEnableMismatch "Charge port controller: a028 insert enable mismatch";
CM_ SG_ 798 CP_a029_doorClosedProxPilot "Charge port controller: a029 door closed prox pilot";
CM_ SG_ 798 CP_a030_busOff "Charge port controller: a030 bus off";
CM_ SG_ 798 CP_a031_doorClosedCommandedOpen "Charge port controller: a031 door closed commanded open";
CM_ SG_ 798 CP_a032_doorOpenExpectedClosed "Charge port controller: a032 door open expected closed";
CM_ SG_ 798 CP_a033_spiOpen "Charge port controller: a033 spi open";
CM_ SG_ 798 CP_a034_calibrationIncomplete "Charge port controller: a034 calibration incomplete";
CM_ SG_ 798 CP_a035_latchMovement_1 "Charge port controller: a035 latch movement 1";
CM_ SG_ 798 CP_a036_latchNotDisengaged "Charge port controller: a036 latch not disengaged";
CM_ SG_ 798 CP_a037_latchNotEngaged "Charge port controller: a037 latch not engaged";
CM_ SG_ 798 CP_a038_latchNotBlocking "Charge port controller: a038 latch not blocking";
CM_ SG_ 798 CP_a039_latchMovement_2 "Charge port controller: a039 latch movement 2";
CM_ SG_ 798 CP_a040_doNotUse "Charge port controller: a040 do not use";
CM_ SG_ 798 CP_a041_doorSensorUnplugged "Charge port controller: a041 door sensor unplugged";
CM_ SG_ 798 CP_a042_doorAssemblyBroken "Charge port controller: a042 door assembly broken";
CM_ SG_ 798 CP_a043_doorPotIrrational "Charge port controller: a043 door pot irrational";
CM_ SG_ 798 CP_a044_lostCommsHVP "Charge port controller: a044 lost comms HVP";
CM_ SG_ 798 CP_a045_lostCommsVCSEC "Charge port controller: a045 lost comms VCSEC";
CM_ SG_ 798 CP_a046_lostCommsEVSE "Charge port controller: a046 lost comms EVSE";
CM_ SG_ 798 CP_a047_lostCommsVCFRONT "Charge port controller: a047 lost comms VCFRONT";
CM_ SG_ 798 CP_a048_lostCommsUI "Charge port controller: a048 lost comms UI";
CM_ SG_ 798 CP_a049_multipleCablesDetected "Charge port controller: a049 multiple cables detected";
CM_ SG_ 798 CP_a050_latchNotConnected "Charge port controller: a050 latch not connected";
CM_ SG_ 798 CP_a051_doorInductiveSensorMIA "Charge port controller: a051 door inductive sensor MIA";
CM_ SG_ 798 CP_a052_chademoNotSupported "Charge port controller: a052 chademo not supported";
CM_ SG_ 798 CP_a053_proxLatchedNoPilot "Charge port controller: a053 prox latched no pilot";
CM_ SG_ 798 CP_a054_cableNotSecured "Charge port controller: a054 cable not secured";
CM_ SG_ 798 CP_a055_chargeStoppedNoPilot "Charge port controller: a055 charge stopped no pilot";
CM_ SG_ 798 CP_a056_proxDisconnected "Charge port controller: a056 prox disconnected";
CM_ SG_ 798 CP_a057_ccs1AdapterBtnPress "Charge port controller: a057 ccs1 adapter btn press";
CM_ SG_ 798 CP_a058_acChargeRetryPending "Charge port controller: a058 ac charge retry pending";
CM_ SG_ 798 CP_a059_swcanError "Charge port controller: a059 swcan error";
CM_ SG_ 798 CP_a060_lostCommsPCS "Charge port controller: a060 lost comms PCS";
CM_ SG_ 798 CP_a061_uhfReceiverMIA "Charge port controller: a061 uhf receiver MIA";
CM_ SG_ 798 CP_a062_scOutOfService "Charge port controller: a062 sc out of service";
CM_ SG_ 798 CP_a063_scUpdateInProgress "Charge port controller: a063 sc update in progress";
CM_ SG_ 798 CP_a064_superchargingBlocked "Charge port controller: a064 supercharging blocked";
CM_ SG_ 798 CP_a065_selfTestFailed "Charge port controller: a065 self test failed";
CM_ SG_ 798 CP_a066_proxLatchedIdlePilot "Charge port controller: a066 prox latched idle pilot";
CM_ SG_ 798 CP_a067_gbdcConnFault "Charge port controller: a067 gbdc conn fault";
CM_ SG_ 798 CP_a068_doorSensorMismatch "Charge port controller: a068 door sensor mismatch";
CM_ SG_ 798 CP_a069_doorInductiveSensorError "Charge port controller: a069 door inductive sensor error";
CM_ SG_ 798 CP_a070_doorInductiveSensorReset "Charge port controller: a070 door inductive sensor reset";
CM_ SG_ 798 CP_a071_exiDecodeFailure "Charge port controller: a071 exi decode failure";
CM_ SG_ 798 CP_a072_v2gEvccTimeout "Charge port controller: a072 v2g evcc timeout";
CM_ SG_ 798 CP_a073_iecComboShutdown "Charge port controller: a073 iec combo shutdown";
CM_ SG_ 798 CP_a074_failedToEstablishV2gComm "Charge port controller: a074 failed to establish v2g comm";
CM_ SG_ 798 CP_a075_v2gCommsFailure "Charge port controller: a075 v2g comms failure";
CM_ SG_ 798 CP_a076_LDC1612errorWatchdog "Charge port controller: a076 ldc1612error watchdog";
CM_ SG_ 798 CP_a077_invalidMacAddress "Charge port controller: a077 invalid mac address";
CM_ SG_ 798 CP_a078_latchNotDisengagedCold "Charge port controller: a078 latch not disengaged cold";
CM_ SG_ 798 CP_a079_cableNotSecuredCold "Charge port controller: a079 cable not secured cold";
CM_ SG_ 798 CP_a080_taskStackOverflow "Charge port controller: a080 task stack overflow";
CM_ SG_ 798 CP_a081_swException "Charge port controller: a081 sw exception";
CM_ SG_ 798 CP_a082_powerOnReset "Charge port controller: a082 power on reset";
CM_ SG_ 798 CP_a083_watchdogTraceData "Charge port controller: a083 watchdog trace data";
CM_ SG_ 798 CP_a084_proxPeDisconnected_gb "Charge port controller: a084 prox pe disconnected gb";
CM_ SG_ 798 CP_a085_dcPinTempFaulted "Charge port controller: a085 dc pin temp faulted";
CM_ SG_ 798 CP_a086_dcPinTempIrrational "Charge port controller: a086 dc pin temp irrational";
CM_ SG_ 798 CP_a087_dcTempModelFault "Charge port controller: a087 dc temp model fault";
CM_ SG_ 798 CP_a088_dcTempModelDeviation "Charge port controller: a088 dc temp model deviation";
CM_ SG_ 798 CP_a089_plcConfigMismatch "Charge port controller: a089 plc config mismatch";
CM_ SG_ 798 CP_a090_ccsEvseLowIso "Charge port controller: a090 ccs evse low iso";
CM_ SG_ 798 CP_a091_wrongSuperchargerHandle "Charge port controller: a091 wrong supercharger handle";
CM_ SG_ 798 CP_a092_modemAppLoadFailed "Charge port controller: a092 modem app load failed";
CM_ SG_ 798 CP_a093_modemLoadedWithReset "Charge port controller: a093 modem loaded with reset";
CM_ SG_ 798 CP_a094_inductiveResetSuccessful "Charge port controller: a094 inductive reset successful";
CM_ SG_ 798 CP_a095_thermalDcLimitActive "Charge port controller: a095 thermal dc limit active";
CM_ SG_ 798 CP_a096_pilotWake "Charge port controller: a096 pilot wake";
CM_ SG_ 798 CP_a097_modeTransitionFailure "Charge port controller: a097 mode transition failure";
CM_ SG_ 798 CP_a098_proximityWake "Charge port controller: a098 proximity wake";
CM_ SG_ 798 CP_a099_cableStateUnknown "Charge port controller: a099 cable state unknown";
CM_ SG_ 798 CP_a100_inletHarnessIdIrrational "Charge port controller: a100 inlet harness id irrational";
CM_ SG_ 798 CP_a101_wcFoldbackActive "Charge port controller: a101 wc foldback active";
CM_ SG_ 798 CP_a102_wcOvertempFault "Charge port controller: a102 wc overtemp fault";
CM_ SG_ 798 CP_a103_proximityPeDisconnected "Charge port controller: a103 proximity pe disconnected";
CM_ SG_ 798 CP_a104_uhfResetSuccessful "Charge port controller: a104 uhf reset successful";
CM_ SG_ 798 CP_a105_hwUnableToSleep "Charge port controller: a105 hw unable to sleep";
CM_ SG_ 798 CP_a106_uhfReceiverReset "Charge port controller: a106 uhf receiver reset";
CM_ SG_ 798 CP_a107_chademoFoldbackActive "Charge port controller: a107 chademo foldback active";
CM_ SG_ 798 CP_a108_chademoOvertempFault "Charge port controller: a108 chademo overtemp fault";
CM_ SG_ 798 CP_a109_thermistorIrrational "Charge port controller: a109 thermistor irrational";
CM_ SG_ 798 CP_a110_thermalVelocityHigh "Charge port controller: a110 thermal velocity high";
CM_ SG_ 798 CP_a111_inletHeaterUnableToHeat "Charge port controller: a111 inlet heater unable to heat";
CM_ SG_ 798 CP_a112_inletHeaterIrrationalTem "Charge port controller: a112 inlet heater irrational temperature";
CM_ SG_ 798 CP_a113_inletHeaterShortCircuit "Charge port controller: a113 inlet heater short circuit";
CM_ SG_ 798 CP_a114_ccsEvseFailed "Charge port controller: a114 ccs evse failed";
CM_ SG_ 798 CP_a115_unexpectedTcan1145State "Charge port controller: a115 unexpected tcan1145 state";
CM_ SG_ 798 CP_a116_misconfigurationDetected "Charge port controller: a116 misconfiguration detected";
CM_ SG_ 798 CP_a117_inletHeaterUnableToRegul "Charge port controller: a117 inlet heater unable to regulate";
CM_ SG_ 798 CP_a118_iecComboLockUp "Charge port controller: a118 iec combo lock up";
CM_ SG_ 798 CP_a119_plcTransmitFailure "Charge port controller: a119 plc transmit failure";
CM_ SG_ 798 CP_a120_comboAdapterFoldback "Charge port controller: a120 combo adapter foldback";
CM_ SG_ 798 CP_a121_PLCRLY_lostCommsCP "Charge port controller: a121 PLCRLY lost comms CP";
CM_ SG_ 798 CP_a122_plcModemFailure "Charge port controller: a122 plc modem failure";
CM_ SG_ 798 CP_a123_latchPotIrrational "Charge port controller: a123 latch pot irrational";
CM_ SG_ 798 CP_a124_ivledFault "Charge port controller: a124 ivled fault";
CM_ SG_ 798 CP_a125_unexpectedLVJuiceState "Charge port controller: a125 unexpected LV juice state";
CM_ SG_ 798 CP_a126_wakeOnUhfFault "Charge port controller: a126 wake on uhf fault";
CM_ SG_ 798 CP_a127_lostCommsHVLINK "Charge port controller: a127 lost comms HVLINK";
CM_ SG_ 798 CP_a128_lostCommsVC "Charge port controller: a128 lost comms VC";
CM_ SG_ 798 CP_a129_bldcDriverCommsFailed "Charge port controller: a129 bldc driver comms failed";
CM_ SG_ 798 CP_a130_bldcDriverCommsRecovered "Charge port controller: a130 bldc driver comms recovered";
CM_ SG_ 798 CP_a131_evseCommTimeout "Charge port controller: a131 evse comm timeout";
CM_ SG_ 798 CP_a132_contractAuthTimeout "Charge port controller: a132 contract auth timeout";
CM_ SG_ 798 CP_a133_proxNeverLatched "Charge port controller: a133 prox never latched";
CM_ SG_ 798 CP_a134_plcModemNotExpected "Charge port controller: a134 plc modem not expected";
CM_ SG_ 798 CP_a135_sdpAttemptsFailed "Charge port controller: a135 sdp attempts failed";
CM_ SG_ 798 CP_a136_sdpSideReqFailed "Charge port controller: a136 sdp side req failed";
CM_ SG_ 798 CP_a137_plcForwardError "Charge port controller: a137 plc forward error";
CM_ SG_ 798 CP_a138_swcanCommsAcEvseFaulted "Charge port controller: a138 swcan comms ac evse faulted";
CM_ SG_ 798 CP_a139_pilotFaulted "Charge port controller: a139 pilot faulted";
CM_ SG_ 798 CP_a140_superchargerFaulted "Charge port controller: a140 supercharger faulted";
CM_ SG_ 798 CP_a141_chademoAdapterFault "Charge port controller: a141 chademo adapter fault";
CM_ SG_ 798 CP_a142_gbdcScConnFault "Charge port controller: a142 gbdc sc conn fault";
CM_ SG_ 798 CP_a143_unsupportedChargeAdapter "Charge port controller: a143 unsupported charge adapter";
CM_ SG_ 798 CP_a144_nvmInitFailed "Charge port controller: a144 nvm init failed";
CM_ SG_ 798 CP_a145_modemAppLoadFailedNA "Charge port controller: a145 modem app load failed NA";
CM_ SG_ 798 CP_a146_ccsEvseMalfunction "Charge port controller: a146 ccs evse malfunction";
CM_ SG_ 798 CP_a147_inductiveRecoveredMia "Charge port controller: a147 inductive recovered mia";
CM_ SG_ 798 CP_a148_bldcTachFeedbackMia "Charge port controller: a148 bldc tach feedback mia";
CM_ SG_ 798 CP_a149_pilotPeriodInvalid "Charge port controller: a149 pilot period invalid";
CM_ SG_ 798 CP_a150_railToggleTimeout "Charge port controller: a150 rail toggle timeout";
CM_ SG_ 798 CP_a151_badPilotDiodeDetected "Charge port controller: a151 bad pilot diode detected";
CM_ SG_ 798 CP_a152_pilotEdgeDetectionFailed "Charge port controller: a152 pilot edge detection failed";
CM_ SG_ 798 CP_a153_thermalAcLimitActive "Charge port controller: a153 thermal ac limit active";
CM_ SG_ 798 CP_a154_acChargingStoppedOT "Charge port controller: a154 ac charging stopped OT";
CM_ SG_ 798 CP_a155_hallPresenceRationality "Charge port controller: a155 hall presence rationality";
CM_ SG_ 798 CP_a156_gbdcPrechargingConcern "Charge port controller: a156 gbdc precharging concern";
CM_ SG_ 798 CP_a157_doorOpenRateLimiter "Charge port controller: a157 door open rate limiter";
CM_ SG_ 798 CP_a158_doorCloseRateLimiter "Charge port controller: a158 door close rate limiter";
CM_ SG_ 798 CP_a159_swcanHealthCheckFailed "Charge port controller: a159 swcan health check failed";
CM_ SG_ 798 CP_a160_latchDisengageInDcCharge "Charge port controller: a160 latch disengage in dc charge";
CM_ SG_ 798 CP_a161_badPilotDiodeDetectedCN "Charge port controller: a161 bad pilot diode detected CN";
CM_ SG_ 798 CP_a162_pilotEdgeDetectionFailed "Charge port controller: a162 pilot edge detection failed CN";
CM_ SG_ 798 CP_a163_coverOpenDcChgBlocked "Charge port controller: a163 cover open dc chg blocked";
CM_ SG_ 798 CP_a164_latchRedisengageRequeste "Charge port controller: a164 latch redisengage requested";
CM_ SG_ 798 CP_a165_proxWiggleDetected "Charge port controller: a165 prox wiggle detected";
CM_ SG_ 798 CP_a166_faultLineMismatchDetecte "Charge port controller: a166 fault line mismatch detected";
CM_ SG_ 798 CP_a167_doorIdIrrational "Charge port controller: a167 door id irrational";
CM_ SG_ 798 CP_a168_pilotHSDFaulted "Charge port controller: a168 pilot HSD faulted";
CM_ SG_ 798 CP_a170_selfTestFailed2 "Charge port controller: a170 self test failed2";
CM_ SG_ 798 CP_a172_triggerOdin "Signal reported by Charge port controller";
CM_ SG_ 798 CP_a173_coverOpenAcChgBlocked "Charge port controller: a173 cover open ac chg blocked";
CM_ SG_ 798 CP_a174_fwdedMsgLoadWarning "Charge port controller: a174 fwded msg load warning";
CM_ SG_ 798 CP_a175_fwdedMsgDropped "Charge port controller: a175 fwded msg dropped";
CM_ SG_ 798 CP_a176_lostCommsV2l "Charge port controller: a176 lost comms v2l";
CM_ SG_ 798 CP_a177_incompatibleV2lDeviceDet "Charge port controller: a177 incompatible v2l device detected";
CM_ SG_ 798 CP_a178_v2xPlcCommsFault "Charge port controller: a178 v2x plc comms fault";
CM_ SG_ 798 CP_a179_evseCommsTlsError "Charge port controller: a179 evse comms tls error";
CM_ SG_ 798 CP_a182_pncdCommsError "Charge port controller: a182 pncd comms error";
CM_ SG_ 798 CP_a183_certManagerError "Charge port controller: a183 cert manager error";
CM_ SG_ 798 CP_a184_certChangeEvent "Charge port controller: a184 cert change event";
CM_ SG_ 798 CP_a185_pncAuthRejection "Charge port controller: a185 pnc auth rejection";
CM_ SG_ 798 CP_a186_spiDmaFailure "Charge port controller: a186 spi dma failure";
CM_ SG_ 798 CP_a187_highStackUsage "Charge port controller: a187 high stack usage";
CM_ SG_ 798 CP_a188_v2lEvseRequiresUpdate "Charge port controller: a188 v2l evse requires update";
CM_ SG_ 798 CP_a189_resistivePresenceRationa "Charge port controller: a189 resistive presence rationality";
CM_ SG_ 798 CP_d190_backCoverCircuitIssue "Charge port controller: d190 back cover circuit issue";
CM_ SG_ 798 CP_d191_latchConnectionIssue "Charge port controller: d191 latch connection issue";
CM_ SG_ 798 CP_d192_couplerTempHigh "Charge port controller: d192 coupler temp high";
CM_ SG_ 798 CP_d193_proximityCircuitErratic "Charge port controller: d193 proximity circuit erratic";
CM_ SG_ 798 CP_d194_proximityCircuitRangeIss "Charge port controller: d194 proximity circuit range issue";
CM_ SG_ 798 CP_d195_couplerLockActuatorIssue "Charge port controller: d195 coupler lock actuator issue";
CM_ SG_ 798 CP_d196_doorActuatorPerformanceI "Charge port controller: d196 door actuator performance issue";
CM_ SG_ 798 CP_d197_doorSensorCircuitErratic "Charge port controller: d197 door sensor circuit erratic";
CM_ SG_ 798 CP_d198_couplerTempSensorCircuit "Charge port controller: d198 coupler temp sensor circuit erratic";
CM_ SG_ 798 CP_d199_hardwareConfigMismatch "Charge port controller: d199 hardware config mismatch";
CM_ SG_ 798 CP_d200_pilotCircuitIssue "Charge port controller: d200 pilot circuit issue";
CM_ SG_ 798 CP_a201_uhfDoorOpenRepeatedlyOve "Charge port controller: a201 uhf door open repeatedly over limit";
CM_ SG_ 798 CP_a202_failedToEstablishV2gComm "Charge port controller: a202 failed to establish v2g comm2";
CM_ SG_ 798 CP_a203_evseCommTimeout2 "Charge port controller: a203 evse comm timeout2";
CM_ SG_ 798 CP_a204_sdpAttemptsFailed2 "Charge port controller: a204 sdp attempts failed2";
CM_ SG_ 798 CP_a205_doorPositionUndetectable "Charge port controller: a205 door position undetectable";
CM_ SG_ 798 CP_a206_peToChassisDisconnected "Charge port controller: a206 pe to chassis disconnected";
CM_ SG_ 798 CP_a207_v2xAuthenticationFailed "Charge port controller: a207 v2x authentication failed";
CM_ SG_ 798 CP_a208_eipmCommsError "Charge port controller: a208 eipm comms error";
CM_ SG_ 798 CP_a209_macphyFault "Charge port controller: a209 macphy fault";
CM_ SG_ 798 CP_a210_lostCommsPCSR "Charge port controller: a210 lost comms PCSR";
CM_ SG_ 798 CP_a211_lostCommsPCSL "Charge port controller: a211 lost comms PCSL";
CM_ SG_ 798 CP_a212_mcsPacketDrops "Charge port controller: a212 mcs packet drops";
CM_ SG_ 798 CP_a213_mcsTcpRetransmitStorm "Charge port controller: a213 mcs tcp retransmit storm";
CM_ SG_ 798 CP_a214_mcsEthDriverRetransmitFa "Charge port controller: a214 mcs eth driver retransmit fail";
CM_ SG_ 798 CP_a215_mcsMacPhyErrors "Charge port controller: a215 mcs mac phy errors";
CM_ SG_ 798 CP_a216_mcsLinkLoss "Charge port controller: a216 mcs link loss";
CM_ SG_ 798 CP_a217_teslaV2gCommsFailure "Charge port controller: a217 tesla v2g comms failure";
CM_ SG_ 798 CP_a218_v2gCommsFailure2 "Charge port controller: a218 v2g comms failure2";
CM_ SG_ 798 CP_a219_doorOpenInDrive "Charge port controller: a219 door open in drive";
CM_ SG_ 798 CP_a220_mcsChargingInterrupted "Charge port controller: a220 mcs charging interrupted";
CM_ SG_ 798 CP_a221_evseStartupTimeout "Charge port controller: a221 evse startup timeout";
CM_ BO_ 317 "Charge port controller message: charge status; frame length from the layout, not yet observed on a vehicle bus";
CM_ SG_ 317 CP_powerTransferStatus "Indicates the state of the charge port power transfer interface.";
CM_ SG_ 317 CP_powerTransferShutdownRequest "Reports the request from the charge port to end a charge session.";
CM_ SG_ 317 CP_evseAcControlMode "Charge port controller: evse ac control mode";
CM_ SG_ 317 CP_v2xCapable "Indicates whether the charge port ECU supports Powershare (V2X) features.";
CM_ SG_ 317 CP_evseAcCurrentLimit "Measures the maximum current the AC EVSE can allow per conductor.";
CM_ SG_ 317 CP_internalMaxDcCurrentLimit "Measures the maximum current the charge port can allow while DC charging.";
CM_ SG_ 317 CP_vehicleIsoCheckRequired "Indicates whether the vehicle is expected to perform isolation monitoring while charging is active.";
CM_ SG_ 317 CP_vehiclePrechargeRequired "Indicates whether the vehicle is expected to perform precharge for the DC charge session.";
CM_ SG_ 317 CP_internalMaxAcCurrentLimit "Measures the maximum current the charge port can allow while AC charging.";
CM_ SG_ 317 CP_evseChargeType "Reports the type of EVSE connected.";
CM_ SG_ 317 CP_chgLimitMode "Reports the reason the charge port is attempting to limit the charge current.";
CM_ SG_ 317 CP_dcHvInletExposed "Indicates whether the direct current (DC) charge port inlet pins are exposed to human touch.";
CM_ SG_ 317 CP_acHvInletExposed "Indicates whether the alternating current (AC) charge port inlet pins are exposed to human touch.";
CM_ BO_ 669 "Charge port controller message: dc charge status; frame length from the layout, not yet observed on a vehicle bus";
CM_ SG_ 669 CP_evseOutputDcCurrent "The DC EVSE's measured output current";
CM_ SG_ 669 CP_evseOutputDcVoltage "The DC EVSE's measured output voltage";
CM_ SG_ 669 CP_evseOutputDcCurrentStale "Indicates whether the data in CP_evseOutputDcCurrent has not been updated with new info from the DC EVSE recently";
CM_ SG_ 669 CP_evRelocationRecommended "Indicates whether the supercharger EVSE recommends relocating the vehicle";
CM_ SG_ 669 CP_evseDeratingReason "Reports the derating reason from Supercharger EVSE";
CM_ BO_ 541 "Charge port controller message: evse status; frame length from the layout, not yet observed on a vehicle bus";
CM_ SG_ 541 CP_evseAccept "State of pilot EVSE accept state";
CM_ SG_ 541 CP_evseRequest "Request to close AC EVSE relays, used when digital communications have been established";
CM_ SG_ 541 CP_proximity "Sensed state of proximity for all inlets; raw 0 = signal not available (SNA)";
CM_ SG_ 541 CP_pilot "State of EVSE pilot signal sensed by the charge port; raw 7 = signal not available (SNA)";
CM_ SG_ 541 CP_digitalCommsEstablished "Indicates whether digital communications have been established with an EVSE";
CM_ SG_ 541 CP_pilotCurrent "Line current limit detected from pilot signal";
CM_ SG_ 541 CP_cableType "Type of charge cable detected; raw 5 = signal not available (SNA)";
CM_ SG_ 541 CP_iecPilotState "State of the control pilot as defined in IEC-61851-1; raw 9 = signal not available (SNA)";
CM_ SG_ 541 CP_plcSupported "Indicates whether PLC hardware is populated for CCS charging support";
CM_ SG_ 541 CP_cableCurrentLimit "Charge port controller: cable current limit";
CM_ SG_ 541 CP_teslaSwcanState "Charge port controller: tesla swcan state";
CM_ SG_ 541 CP_evseChargeType_UI "Reports the type of Electric Vehicle Supply Equipment (EVSE) connected.";
CM_ SG_ 541 CP_gbState "State of GB DC charging";
CM_ SG_ 541 CP_gbdcStopChargeReason "Reason for stopping GB DC charging";
CM_ SG_ 541 CP_gbdcFailureReason "Reason for failure of GB DC charging";
CM_ SG_ 541 CP_gbdcChargeAttempts "Number of GB DC charging retries used";
CM_ SG_ 541 CP_acChargeState "Charge port controller: ac charge state";
CM_ SG_ 541 CP_acChargeType "Charge port controller: ac charge type";
CM_ SG_ 541 CP_teslaDcState "Reports the state of the Tesla direct current (DC) state machine.";
CM_ BO_ 733 "Charge port controller message: grid form control; frame length from the layout, not yet observed on a vehicle bus";
CM_ SG_ 733 CP_gridFormFrequencyRequest "Charge port controller: grid form frequency request; raw 4095 = signal not available (SNA)";
CM_ SG_ 733 CP_gridFormL1NVoltageRequest "Charge port controller: grid form L1 n voltage request; raw 255 = signal not available (SNA)";
CM_ SG_ 733 CP_gridFormGroundType "Charge port controller: grid form ground type; raw 0 = signal not available (SNA)";
CM_ SG_ 733 CP_gridFormGridType "Charge port controller: grid form grid type; raw 0 = signal not available (SNA)";
CM_ SG_ 733 CP_powershareType "Charge port controller: powershare type";
CM_ SG_ 733 CP_userPowershareStatus "Charge port controller: user powershare status";
CM_ SG_ 733 CP_powershareStoppedReason "Charge port controller: powershare stopped reason";
CM_ BO_ 1342 "Charge port controller message: info; frame length from the layout, not yet observed on a vehicle bus";
CM_ SG_ 1342 CP_infoIndex "Charge port controller: info index";
CM_ SG_ 1342 CP_buildType "Charge port controller: build type";
CM_ SG_ 1342 CP_buildConfigId "Charge port controller: build config id";
CM_ SG_ 1342 CP_hardwareId "Charge port controller: hardware id";
CM_ SG_ 1342 CP_componentId "Charge port controller: component id";
CM_ SG_ 1342 CP_pcbaId "Charge port controller: pcba id";
CM_ SG_ 1342 CP_assemblyId "Charge port controller: assembly id";
CM_ SG_ 1342 CP_usageId "Charge port controller: usage id";
CM_ SG_ 1342 CP_subUsageId "Charge port controller: sub usage id";
CM_ SG_ 1342 CP_platformType "Charge port controller: platform type";
CM_ SG_ 1342 CP_appCrc "Charge port controller: app crc";
CM_ SG_ 1342 CP_appGitHash "Charge port controller: app git hash";
CM_ SG_ 1342 CP_bootGitHash "Charge port controller: boot git hash";
CM_ SG_ 1342 CP_bootUdsProtoVersion "Charge port controller: boot uds proto version";
CM_ SG_ 1342 CP_bootCrc "Charge port controller: boot crc";
CM_ BO_ 1885 "Charge port controller message: logging fast; frame length from the layout, not yet observed on a vehicle bus";
CM_ SG_ 1885 CP_loggingFastSelect "Charge port controller: logging fast select";
CM_ SG_ 1885 CP_inductiveSensor_raw "Charge port controller: inductive sensor raw";
CM_ SG_ 1885 CP_doorOpenActuationTime "Charge port controller: door open actuation time";
CM_ SG_ 1885 CP_doorCloseActuationTime "Charge port controller: door close actuation time";
CM_ SG_ 1885 CP_chargeCableSecured "Indicates whether a charge cable is secured in any inlet";
CM_ SG_ 1885 CP_chargeCablePresent "Indicates whether a charge cable is present in any inlet";
CM_ SG_ 1885 CP_latchCheckAvailable "Charge port controller: latch check available";
CM_ SG_ 1885 CP_UHF_controlState "Control state of UHF receiver";
CM_ SG_ 1885 CP_proximityV "Charge port controller: proximity v";
CM_ SG_ 1885 CP_proximityV_GBCC1 "Sensed voltage of GB DC inlet CC1 connection";
CM_ SG_ 1885 CP_proximityV_GBCC2 "Sensed voltage of GB DC inlet CC2 connection";
CM_ SG_ 1885 CP_doorPot "Position of the charge port door potentiometer";
CM_ SG_ 1885 CP_doorPresenceSensorV "Reports voltage value read by the charge port door's presence sensor.";
CM_ SG_ 1885 CP_doorOpenRequest "Door open request trigger";
CM_ SG_ 1885 CP_doorOpenEndOfDriveReason "Reason why the door stopped moving in the open direction";
CM_ SG_ 1885 CP_coverClosed "Charge port controller: cover closed";
CM_ SG_ 1885 CP_doorCloseEndOfDriveReason "Reason why the door stopped moving in the closing direction";
CM_ SG_ 1885 CP_doorCloseRequest "Door close request trigger";
CM_ SG_ 1885 CP_latchDisengagingTime "Charge port controller: latch disengaging time";
CM_ SG_ 1885 CP_latchEngagingTime "Charge port controller: latch engaging time";
CM_ SG_ 1885 CP_latchDisengagingStopReason "Reason why the latch stopped moving in the engaged direction";
CM_ SG_ 1885 CP_latchEngagingStopReason "Reason why the latch stopped moving in the engaged direction";
CM_ SG_ 1885 CP_pilotUnlatchRequestActive "Reports whether the Charge Port (CP) pilot unlatch request is active.";
CM_ SG_ 1885 CP_doorIdDetectionState "Charge port controller: door id detection state; raw 0 = signal not available (SNA)";
CM_ SG_ 1885 CP_doorIdDetectedBin "Charge port controller: door id detected bin";
CM_ SG_ 1885 CP_semiV2LatchNonLinear "Reports whether the Charge Port (CP) SemiV2 latch potentiometer reading is non-linear.";
CM_ BO_ 989 "Charge port controller message: logging slow; frame length from the layout, not yet observed on a vehicle bus";
CM_ SG_ 989 CP_loggingSlowSelect "Charge port controller: logging slow select";
CM_ SG_ 989 CP_UHF_chipState "Charge port controller: UHF chip state";
CM_ SG_ 989 CP_UHF_rssi "Signal strength of received UHF signal";
CM_ SG_ 989 CP_UHF_rxOverflow "Charge port controller: UHF rx overflow";
CM_ SG_ 989 CP_UHF_rxNumBytes "Charge port controller: UHF rx num bytes";
CM_ SG_ 989 CP_UHF_selfTestRssi "Signal strength of received self-test UHF signal";
CM_ SG_ 989 CP_latchI "Charge port controller: latch i";
CM_ SG_ 989 CP_inlet1HarnessIdState "State of the CP's inlet 1 harness pedigree; raw 0 = signal not available (SNA)";
CM_ SG_ 989 CP_inlet1HarnessIdValue "Pedigree of the CP's inlet 1 harness";
CM_ SG_ 989 CP_inlet2HarnessIdState "State of the CP's inlet 2 harness pedigree; raw 0 = signal not available (SNA)";
CM_ SG_ 989 CP_inlet2HarnessIdValue "Pedigree of the CP's inlet 2 harness";
CM_ SG_ 989 CP_inletHeaterState "Reports the present state of the inlet heater.";
CM_ SG_ 989 CP_inletHeaterDuty "Inlet heater PWM duty cycle";
CM_ SG_ 989 CP_5vSwV "Charge port controller: 5v sw v";
CM_ SG_ 989 CP_boardTemperature "Charge port controller: board temperature";
CM_ SG_ 989 CP_refVoltage "Charge port controller: ref voltage";
CM_ SG_ 989 CP_doorId_intervalMin10s "Charge port controller: door id interval min10s";
CM_ SG_ 989 CP_doorId_intervalMax10s "Charge port controller: door id interval max10s";
CM_ SG_ 989 CP_wakeOnPushCounter "Charge port controller: wake on push counter";
CM_ SG_ 989 CP_doorPushLockoutActive "Reports whether the Charge Port (CP) wake on press has been disabled due to rate-limiting.";
CM_ SG_ 989 CP_nvm_dataValid "Charge port controller: nvm data valid";
CM_ SG_ 989 CP_nvm_doorOpenCycles "Charge port controller: nvm door open cycles";
CM_ SG_ 989 CP_nvm_doorCloseCycles "Charge port controller: nvm door close cycles";
CM_ SG_ 989 CP_nvm_doorOpen "Charge port controller: nvm door open";
CM_ SG_ 989 CP_nvm_doorPresent "Charge port controller: nvm door present";
CM_ SG_ 989 CP_nvm_doorPresentValid "Charge port controller: nvm door present valid";
CM_ SG_ 989 CP_nvm_badPilotDiodeDetected "Charge port controller: nvm bad pilot diode detected";
CM_ SG_ 989 CP_nvm_pilotDiodeFaultCount "Charge port controller: nvm pilot diode fault count";
CM_ SG_ 989 CP_doorOpenLimiterMaxCount "Charge port controller: door open limiter max count";
CM_ SG_ 989 CP_doorOpenLimiterMaxRequestType "Charge port controller: door open limiter max request type";
CM_ SG_ 989 CP_doorCloseLimiterMaxCount "Charge port controller: door close limiter max count";
CM_ SG_ 989 CP_doorCloseLimiterMaxRequestTyp "Charge port controller: door close limiter max request type";
CM_ SG_ 989 CP_proximityWakeCounter "Charge port controller: proximity wake counter";
CM_ BO_ 605 "Charge port controller message: status; frame length from the layout, not yet observed on a vehicle bus";
CM_ SG_ 605 CP_type "Charge port controller: type";
CM_ SG_ 605 CP_insertEnableLine "Sensed state of the charge port latch drive enable hardline";
CM_ SG_ 605 CP_latchState "Sensed state of the charge port latch; raw 0 = signal not available (SNA)";
CM_ SG_ 605 CP_permanentPowerRequest "Charge port controller: permanent power request";
CM_ SG_ 605 CP_chargeDoorOpen "Indicates whether the charge port door is open based on all door sensors";
CM_ SG_ 605 CP_doorControlState "State of the charge port door controller";
CM_ SG_ 605 CP_doorButtonPressed "Indicates whether the charge door button has been pressed";
CM_ SG_ 605 CP_swcanRelayClosed "Indicates whether the single wire CAN relay is closed";
CM_ SG_ 605 CP_inhibitOta "Reports the charge port's request to prevent scheduled Over-The-Air (OTA) updates during critical charging operations.";
CM_ SG_ 605 CP_chargeCableState "Charge cable connection state; raw 0 = signal not available (SNA)";
CM_ SG_ 605 CP_latchControlState "Control state of the charge port latch";
CM_ SG_ 605 CP_ledColor "Color of the charge port LED";
CM_ SG_ 605 CP_UHF_handleFound "Indicates whether a charge handle has been found with UHF";
CM_ SG_ 605 CP_faultLineSensed "A signal indicating the set / cleared state of the CP-HVP bi-directional fault line, as sensed by the CP";
CM_ SG_ 605 CP_doorPresenceState "State of door as detected by the presence sensor";
CM_ SG_ 605 CP_inductiveSensorState "State of inductive door sensor";
CM_ SG_ 605 CP_chargeDoorOpenUI "Indicates whether the charge port door is open based only on the door poteniometer";
CM_ SG_ 605 CP_vehicleUnlockRequest "Request to unlock the vehicle";
CM_ SG_ 605 CP_coldWeatherMode "Indicates whether the charge port is in cold weather mode";
CM_ SG_ 605 CP_latchEngaged "Charge port controller: latch engaged";
CM_ SG_ 605 CP_inletHeaterUiState "Reports to the User Interface (UI) the state of the inlet heater.";
CM_ SG_ 605 CP_userEvseModelType "Reports the type of Electric Vehicle Supply Equipment (EVSE) model to display to the user.";
CM_ SG_ 605 CP_evseGridFormHardwareType "Reports Electric Vehicle Supply Equipment (EVSE) grid form hardware type for grid forming; raw 15 = signal not available (SNA)";
CM_ SG_ 605 CP_faultLineV "Charge port controller: fault line v";
CM_ SG_ 605 CP_faultLineSetByCP "Reports that the Charge Port (CP) triggered the hardware fault line.";
CM_ SG_ 605 CP_AuthManagerState "Charge port controller: auth manager state";
CM_ BO_ 893 "Charge port controller message: thermal status; frame length from the layout, not yet observed on a vehicle bus";
CM_ SG_ 893 CP_thermalStatusSelect "Charge port controller: thermal status select";
CM_ SG_ 893 CP_pinTemperature1 "Sensed temperature of the charge port inlet pins";
CM_ SG_ 893 CP_pinTemperature2 "Sensed temperature of the charge port inlet pins";
CM_ SG_ 893 CP_pinTemperature3 "Sensed temperature of the charge port inlet pins";
CM_ SG_ 893 CP_pinTemperature4 "Sensed temperature of the charge port inlet pins";
CM_ SG_ 893 CP_pinTemp4Velocity "Instantaneous temperature velocity (over 1 minute) of Charge Port's temperature 4; raw 511 = signal not available (SNA)";
CM_ BO_ 1566 "Charge port controller message: uds response; frame length from the layout, not yet observed on a vehicle bus";
CM_ SG_ 1566 CP_udsResponseData "Charge port controller: uds response data";
CM_ BO_ 1001 "Driver assistance computer message: body controls; frame length from the layout, not yet observed on a vehicle bus";
CM_ SG_ 1001 DAS_headlightRequest "The DAS request to the body controls ecu to turn on headlights.";
CM_ SG_ 1001 DAS_hazardLightRequest "The command from DAS to body controls to turn on the hazard lights; raw 3 = signal not available (SNA)";
CM_ SG_ 1001 DAS_wiperSpeed "The auto wiper algorithm speed request to the body controller.";
CM_ SG_ 1001 DAS_turnIndicatorRequest "Reports Driver Assistance System (DAS) request to body controls to turn on/off the left or right turn indicator.";
CM_ SG_ 1001 DAS_highLowBeamDecision "The output of the automatic high beam algorithm, to turn the highbeams on or off; raw 3 = signal not available (SNA)";
CM_ SG_ 1001 DAS_heaterRequest "The DAS request to the body controller to turn on the front glass heater in front of the triple camera; raw 0 = signal not available (SNA)";
CM_ SG_ 1001 DAS_highLowBeamOffReason "The reason why automatic high beams are surpressed; raw 5 = signal not available (SNA)";
CM_ SG_ 1001 DAS_forwardCamHeaterDutyCycle "Supplies the requested duty cycle of the front windshield camera heater";
CM_ SG_ 1001 DAS_dynamicBrakeLightRequest "Indicates if the dynamic brake light alogirthm is requesting pulsing brake lights.";
CM_ SG_ 1001 DAS_radarHeaterRequest "Reports the request from Driver Assistance System (DAS) to body controls to turn on heater to clear out fascia in front of the radar.";
CM_ SG_ 1001 DAS_ahlbOverride "Indicates if body controller should override UI switch and stalk state to allow auto high beam functionality";
CM_ SG_ 1001 DAS_mirrorFoldRequest "DAS request to fold or present mirrors; raw 3 = signal not available (SNA)";
CM_ SG_ 1001 DAS_wiperWashRequest "Autowiper requests that the windshield be washed";
CM_ SG_ 1001 DAS_ulcConfirmationRequestActive "Driver assistance computer: ulc confirmation request active";
CM_ SG_ 1001 DAS_overrideWiperSetting "Autopilot wants to override the user's wiper setting to enable auto-wiper";
CM_ SG_ 1001 DAS_autoWiperState "DAS auto wiper internal state; raw 5 = signal not available (SNA)";
CM_ SG_ 1001 DAS_turnIndicatorRequestReason "Reports the reason that Driver Assistance System (DAS) is requesting a change to the turn indicator state from body controls.";
CM_ SG_ 1001 DAS_forwardRadarPowerRequest "Driver assistance computer: forward radar power request";
CM_ SG_ 1001 DAS_driverDomeLightRequest "DAS requests that driver side dome light be illuminated";
CM_ SG_ 1001 DAS_drivePowerStateRequest "Reports DAS request for vehicle power state Drive.";
CM_ SG_ 1001 DAS_enableIcrDataCollection "Driver assistance computer: enable icr data collection";
CM_ SG_ 1001 DAS_rPillarCamHeaterDutyCycle "Supplies the requested duty cycle of the right pillar camera heater";
CM_ SG_ 1001 DAS_adaptiveHighBeamIsFaulted "Indicates malfunctioning or unavailable input to the Adaptive High Beam system.";
CM_ SG_ 1001 DAS_restrictDoorReleaseLeft "Reports requests to inhibit left doors from being released.";
CM_ SG_ 1001 DAS_restrictDoorReleaseRight "Reports requests to inhibit right doors from being released.";
CM_ SG_ 1001 DAS_bodyControlsCounter "Driver assistance computer: body controls counter";
CM_ SG_ 1001 DAS_bodyControlsChecksum "Driver assistance computer: body controls checksum";
BA_DEF_ BO_ "GenMsgCycleTime" INT 0 3600000;
BA_DEF_ BO_ "GenMsgSendType" ENUM "Cyclic","NotUsed","NotUsed","NotUsed","NotUsed","NotUsed","NotUsed","IfActive","NoMsgSendType","NotUsed";
BA_DEF_ BO_ "VFrameFormat" ENUM "StandardCAN","ExtendedCAN","reserved","J1939PG","reserved","reserved","reserved","reserved","reserved","reserved","reserved","reserved","reserved","reserved","StandardCAN_FD","ExtendedCAN_FD";
BA_DEF_ BO_ "CANFD_BRS" ENUM "0","1";
BA_DEF_ SG_ "GenSigSNA" STRING;
BA_DEF_ SG_ "SystemSignalLongSymbol" STRING;
BA_DEF_ SG_ "Confidence" ENUM "validated","plausible","layout-only","contradicted";
BA_DEF_DEF_ "GenMsgCycleTime" 0;
BA_DEF_DEF_ "GenMsgSendType" "NoMsgSendType";
BA_DEF_DEF_ "VFrameFormat" "StandardCAN";
BA_DEF_DEF_ "CANFD_BRS" "1";
BA_DEF_DEF_ "GenSigSNA" "";
BA_DEF_DEF_ "SystemSignalLongSymbol" "";
BA_DEF_DEF_ "Confidence" "layout-only";
BA_ "GenMsgCycleTime" BO_ 798 1000;
BA_ "GenMsgSendType" BO_ 798 0;
BA_ "GenMsgCycleTime" BO_ 317 100;
BA_ "GenMsgSendType" BO_ 317 0;
BA_ "GenMsgCycleTime" BO_ 669 100;
BA_ "GenMsgSendType" BO_ 669 0;
BA_ "GenMsgCycleTime" BO_ 541 100;
BA_ "GenMsgSendType" BO_ 541 0;
BA_ "GenMsgCycleTime" BO_ 733 1000;
BA_ "GenMsgSendType" BO_ 733 0;
BA_ "GenMsgCycleTime" BO_ 1342 1000;
BA_ "GenMsgSendType" BO_ 1342 0;
BA_ "GenMsgCycleTime" BO_ 1885 200;
BA_ "GenMsgSendType" BO_ 1885 0;
BA_ "GenMsgCycleTime" BO_ 989 1000;
BA_ "GenMsgSendType" BO_ 989 0;
BA_ "GenMsgCycleTime" BO_ 605 100;
BA_ "GenMsgSendType" BO_ 605 0;
BA_ "GenMsgCycleTime" BO_ 893 1000;
BA_ "GenMsgSendType" BO_ 893 0;
BA_ "GenMsgCycleTime" BO_ 1001 500;
BA_ "GenMsgSendType" BO_ 1001 0;
BA_ "Confidence" SG_ 798 CP_matrixIndex 1;
BA_ "SystemSignalLongSymbol" SG_ 798 CP_a112_inletHeaterIrrationalTem "CP_a112_inletHeaterIrrationalTemperature";
BA_ "SystemSignalLongSymbol" SG_ 798 CP_a117_inletHeaterUnableToRegul "CP_a117_inletHeaterUnableToRegulate";
BA_ "SystemSignalLongSymbol" SG_ 798 CP_a162_pilotEdgeDetectionFailed "CP_a162_pilotEdgeDetectionFailedCN";
BA_ "SystemSignalLongSymbol" SG_ 798 CP_a164_latchRedisengageRequeste "CP_a164_latchRedisengageRequested";
BA_ "SystemSignalLongSymbol" SG_ 798 CP_a166_faultLineMismatchDetecte "CP_a166_faultLineMismatchDetected";
BA_ "SystemSignalLongSymbol" SG_ 798 CP_a177_incompatibleV2lDeviceDet "CP_a177_incompatibleV2lDeviceDetected";
BA_ "SystemSignalLongSymbol" SG_ 798 CP_a189_resistivePresenceRationa "CP_a189_resistivePresenceRationality";
BA_ "SystemSignalLongSymbol" SG_ 798 CP_d194_proximityCircuitRangeIss "CP_d194_proximityCircuitRangeIssue";
BA_ "SystemSignalLongSymbol" SG_ 798 CP_d196_doorActuatorPerformanceI "CP_d196_doorActuatorPerformanceIssue";
BA_ "SystemSignalLongSymbol" SG_ 798 CP_d198_couplerTempSensorCircuit "CP_d198_couplerTempSensorCircuitErratic";
BA_ "SystemSignalLongSymbol" SG_ 798 CP_a201_uhfDoorOpenRepeatedlyOve "CP_a201_uhfDoorOpenRepeatedlyOverLimit";
BA_ "SystemSignalLongSymbol" SG_ 798 CP_a202_failedToEstablishV2gComm "CP_a202_failedToEstablishV2gComm2";
BA_ "SystemSignalLongSymbol" SG_ 798 CP_a214_mcsEthDriverRetransmitFa "CP_a214_mcsEthDriverRetransmitFail";
BA_ "Confidence" SG_ 317 CP_powerTransferStatus 0;
BA_ "Confidence" SG_ 317 CP_powerTransferShutdownRequest 0;
BA_ "Confidence" SG_ 317 CP_evseAcControlMode 0;
BA_ "Confidence" SG_ 317 CP_v2xCapable 0;
BA_ "Confidence" SG_ 317 CP_evseAcCurrentLimit 0;
BA_ "Confidence" SG_ 317 CP_internalMaxDcCurrentLimit 0;
BA_ "Confidence" SG_ 317 CP_vehicleIsoCheckRequired 0;
BA_ "Confidence" SG_ 317 CP_vehiclePrechargeRequired 0;
BA_ "Confidence" SG_ 317 CP_internalMaxAcCurrentLimit 0;
BA_ "Confidence" SG_ 317 CP_evseChargeType 0;
BA_ "Confidence" SG_ 317 CP_chgLimitMode 0;
BA_ "Confidence" SG_ 317 CP_dcHvInletExposed 0;
BA_ "Confidence" SG_ 317 CP_acHvInletExposed 0;
BA_ "Confidence" SG_ 669 CP_evseOutputDcCurrent 0;
BA_ "Confidence" SG_ 669 CP_evseOutputDcVoltage 0;
BA_ "Confidence" SG_ 669 CP_evseOutputDcCurrentStale 0;
BA_ "Confidence" SG_ 669 CP_evRelocationRecommended 0;
BA_ "Confidence" SG_ 669 CP_evseDeratingReason 0;
BA_ "Confidence" SG_ 541 CP_evseAccept 0;
BA_ "Confidence" SG_ 541 CP_evseRequest 0;
BA_ "Confidence" SG_ 541 CP_proximity 0;
BA_ "GenSigSNA" SG_ 541 CP_proximity "0";
BA_ "Confidence" SG_ 541 CP_pilot 0;
BA_ "GenSigSNA" SG_ 541 CP_pilot "7";
BA_ "Confidence" SG_ 541 CP_digitalCommsEstablished 0;
BA_ "Confidence" SG_ 541 CP_pilotCurrent 0;
BA_ "Confidence" SG_ 541 CP_cableType 0;
BA_ "GenSigSNA" SG_ 541 CP_cableType "5";
BA_ "Confidence" SG_ 541 CP_iecPilotState 0;
BA_ "GenSigSNA" SG_ 541 CP_iecPilotState "9";
BA_ "Confidence" SG_ 541 CP_plcSupported 0;
BA_ "Confidence" SG_ 541 CP_cableCurrentLimit 0;
BA_ "Confidence" SG_ 541 CP_teslaSwcanState 0;
BA_ "Confidence" SG_ 541 CP_evseChargeType_UI 0;
BA_ "Confidence" SG_ 541 CP_gbState 0;
BA_ "Confidence" SG_ 541 CP_gbdcStopChargeReason 0;
BA_ "Confidence" SG_ 541 CP_gbdcFailureReason 0;
BA_ "Confidence" SG_ 541 CP_gbdcChargeAttempts 0;
BA_ "Confidence" SG_ 541 CP_acChargeState 0;
BA_ "Confidence" SG_ 541 CP_acChargeType 0;
BA_ "Confidence" SG_ 541 CP_teslaDcState 0;
BA_ "Confidence" SG_ 733 CP_gridFormFrequencyRequest 0;
BA_ "GenSigSNA" SG_ 733 CP_gridFormFrequencyRequest "4095";
BA_ "Confidence" SG_ 733 CP_gridFormL1NVoltageRequest 0;
BA_ "GenSigSNA" SG_ 733 CP_gridFormL1NVoltageRequest "255";
BA_ "Confidence" SG_ 733 CP_gridFormGroundType 0;
BA_ "GenSigSNA" SG_ 733 CP_gridFormGroundType "0";
BA_ "Confidence" SG_ 733 CP_gridFormGridType 0;
BA_ "GenSigSNA" SG_ 733 CP_gridFormGridType "0";
BA_ "Confidence" SG_ 733 CP_powershareType 0;
BA_ "Confidence" SG_ 733 CP_userPowershareStatus 0;
BA_ "Confidence" SG_ 733 CP_powershareStoppedReason 0;
BA_ "Confidence" SG_ 1342 CP_infoIndex 1;
BA_ "Confidence" SG_ 1342 CP_buildType 0;
BA_ "Confidence" SG_ 1342 CP_buildConfigId 0;
BA_ "Confidence" SG_ 1342 CP_hardwareId 0;
BA_ "Confidence" SG_ 1342 CP_componentId 0;
BA_ "Confidence" SG_ 1342 CP_pcbaId 0;
BA_ "Confidence" SG_ 1342 CP_assemblyId 0;
BA_ "Confidence" SG_ 1342 CP_usageId 0;
BA_ "Confidence" SG_ 1342 CP_subUsageId 0;
BA_ "Confidence" SG_ 1342 CP_platformType 0;
BA_ "Confidence" SG_ 1342 CP_appCrc 0;
BA_ "Confidence" SG_ 1342 CP_appGitHash 0;
BA_ "Confidence" SG_ 1342 CP_bootGitHash 0;
BA_ "Confidence" SG_ 1342 CP_bootUdsProtoVersion 0;
BA_ "Confidence" SG_ 1342 CP_bootCrc 0;
BA_ "Confidence" SG_ 1885 CP_loggingFastSelect 1;
BA_ "Confidence" SG_ 1885 CP_inductiveSensor_raw 0;
BA_ "Confidence" SG_ 1885 CP_doorOpenActuationTime 0;
BA_ "Confidence" SG_ 1885 CP_doorCloseActuationTime 0;
BA_ "Confidence" SG_ 1885 CP_chargeCableSecured 0;
BA_ "Confidence" SG_ 1885 CP_chargeCablePresent 0;
BA_ "Confidence" SG_ 1885 CP_latchCheckAvailable 0;
BA_ "Confidence" SG_ 1885 CP_UHF_controlState 0;
BA_ "Confidence" SG_ 1885 CP_proximityV 0;
BA_ "Confidence" SG_ 1885 CP_proximityV_GBCC1 0;
BA_ "Confidence" SG_ 1885 CP_proximityV_GBCC2 0;
BA_ "Confidence" SG_ 1885 CP_doorPot 0;
BA_ "Confidence" SG_ 1885 CP_doorPresenceSensorV 0;
BA_ "Confidence" SG_ 1885 CP_doorOpenRequest 0;
BA_ "Confidence" SG_ 1885 CP_doorOpenEndOfDriveReason 0;
BA_ "Confidence" SG_ 1885 CP_coverClosed 0;
BA_ "Confidence" SG_ 1885 CP_doorCloseEndOfDriveReason 0;
BA_ "Confidence" SG_ 1885 CP_doorCloseRequest 0;
BA_ "Confidence" SG_ 1885 CP_latchDisengagingTime 0;
BA_ "Confidence" SG_ 1885 CP_latchEngagingTime 0;
BA_ "Confidence" SG_ 1885 CP_latchDisengagingStopReason 0;
BA_ "Confidence" SG_ 1885 CP_latchEngagingStopReason 0;
BA_ "Confidence" SG_ 1885 CP_pilotUnlatchRequestActive 0;
BA_ "Confidence" SG_ 1885 CP_doorIdDetectionState 0;
BA_ "GenSigSNA" SG_ 1885 CP_doorIdDetectionState "0";
BA_ "Confidence" SG_ 1885 CP_doorIdDetectedBin 0;
BA_ "Confidence" SG_ 1885 CP_semiV2LatchNonLinear 0;
BA_ "Confidence" SG_ 989 CP_loggingSlowSelect 1;
BA_ "Confidence" SG_ 989 CP_UHF_chipState 0;
BA_ "Confidence" SG_ 989 CP_UHF_rssi 0;
BA_ "Confidence" SG_ 989 CP_UHF_rxOverflow 0;
BA_ "Confidence" SG_ 989 CP_UHF_rxNumBytes 0;
BA_ "Confidence" SG_ 989 CP_UHF_selfTestRssi 0;
BA_ "Confidence" SG_ 989 CP_latchI 0;
BA_ "Confidence" SG_ 989 CP_inlet1HarnessIdState 0;
BA_ "GenSigSNA" SG_ 989 CP_inlet1HarnessIdState "0";
BA_ "Confidence" SG_ 989 CP_inlet1HarnessIdValue 0;
BA_ "Confidence" SG_ 989 CP_inlet2HarnessIdState 0;
BA_ "GenSigSNA" SG_ 989 CP_inlet2HarnessIdState "0";
BA_ "Confidence" SG_ 989 CP_inlet2HarnessIdValue 0;
BA_ "Confidence" SG_ 989 CP_inletHeaterState 0;
BA_ "Confidence" SG_ 989 CP_inletHeaterDuty 0;
BA_ "Confidence" SG_ 989 CP_5vSwV 0;
BA_ "Confidence" SG_ 989 CP_boardTemperature 0;
BA_ "Confidence" SG_ 989 CP_refVoltage 0;
BA_ "Confidence" SG_ 989 CP_doorId_intervalMin10s 0;
BA_ "Confidence" SG_ 989 CP_doorId_intervalMax10s 0;
BA_ "Confidence" SG_ 989 CP_wakeOnPushCounter 0;
BA_ "Confidence" SG_ 989 CP_doorPushLockoutActive 0;
BA_ "Confidence" SG_ 989 CP_nvm_dataValid 0;
BA_ "Confidence" SG_ 989 CP_nvm_doorOpenCycles 0;
BA_ "Confidence" SG_ 989 CP_nvm_doorCloseCycles 0;
BA_ "Confidence" SG_ 989 CP_nvm_doorOpen 0;
BA_ "Confidence" SG_ 989 CP_nvm_doorPresent 0;
BA_ "Confidence" SG_ 989 CP_nvm_doorPresentValid 0;
BA_ "Confidence" SG_ 989 CP_nvm_badPilotDiodeDetected 0;
BA_ "Confidence" SG_ 989 CP_nvm_pilotDiodeFaultCount 0;
BA_ "Confidence" SG_ 989 CP_doorOpenLimiterMaxCount 0;
BA_ "Confidence" SG_ 989 CP_doorOpenLimiterMaxRequestType 0;
BA_ "Confidence" SG_ 989 CP_doorCloseLimiterMaxCount 0;
BA_ "Confidence" SG_ 989 CP_doorCloseLimiterMaxRequestTyp 0;
BA_ "SystemSignalLongSymbol" SG_ 989 CP_doorCloseLimiterMaxRequestTyp "CP_doorCloseLimiterMaxRequestType";
BA_ "Confidence" SG_ 989 CP_proximityWakeCounter 0;
BA_ "Confidence" SG_ 605 CP_type 0;
BA_ "Confidence" SG_ 605 CP_insertEnableLine 0;
BA_ "Confidence" SG_ 605 CP_latchState 0;
BA_ "GenSigSNA" SG_ 605 CP_latchState "0";
BA_ "Confidence" SG_ 605 CP_permanentPowerRequest 0;
BA_ "Confidence" SG_ 605 CP_chargeDoorOpen 0;
BA_ "Confidence" SG_ 605 CP_doorControlState 0;
BA_ "Confidence" SG_ 605 CP_doorButtonPressed 0;
BA_ "Confidence" SG_ 605 CP_swcanRelayClosed 0;
BA_ "Confidence" SG_ 605 CP_inhibitOta 0;
BA_ "Confidence" SG_ 605 CP_chargeCableState 0;
BA_ "GenSigSNA" SG_ 605 CP_chargeCableState "0";
BA_ "Confidence" SG_ 605 CP_latchControlState 0;
BA_ "Confidence" SG_ 605 CP_ledColor 0;
BA_ "Confidence" SG_ 605 CP_UHF_handleFound 0;
BA_ "Confidence" SG_ 605 CP_faultLineSensed 0;
BA_ "Confidence" SG_ 605 CP_doorPresenceState 0;
BA_ "Confidence" SG_ 605 CP_inductiveSensorState 0;
BA_ "Confidence" SG_ 605 CP_chargeDoorOpenUI 0;
BA_ "Confidence" SG_ 605 CP_vehicleUnlockRequest 0;
BA_ "Confidence" SG_ 605 CP_coldWeatherMode 0;
BA_ "Confidence" SG_ 605 CP_latchEngaged 0;
BA_ "Confidence" SG_ 605 CP_inletHeaterUiState 0;
BA_ "Confidence" SG_ 605 CP_userEvseModelType 0;
BA_ "Confidence" SG_ 605 CP_evseGridFormHardwareType 0;
BA_ "GenSigSNA" SG_ 605 CP_evseGridFormHardwareType "15";
BA_ "Confidence" SG_ 605 CP_faultLineV 0;
BA_ "Confidence" SG_ 605 CP_faultLineSetByCP 0;
BA_ "Confidence" SG_ 605 CP_AuthManagerState 0;
BA_ "Confidence" SG_ 893 CP_thermalStatusSelect 1;
BA_ "Confidence" SG_ 893 CP_pinTemperature1 0;
BA_ "Confidence" SG_ 893 CP_pinTemperature2 0;
BA_ "Confidence" SG_ 893 CP_pinTemperature3 0;
BA_ "Confidence" SG_ 893 CP_pinTemperature4 0;
BA_ "Confidence" SG_ 893 CP_pinTemp4Velocity 0;
BA_ "GenSigSNA" SG_ 893 CP_pinTemp4Velocity "511";
BA_ "Confidence" SG_ 1566 CP_udsResponseData 1;
BA_ "Confidence" SG_ 1001 DAS_headlightRequest 0;
BA_ "Confidence" SG_ 1001 DAS_hazardLightRequest 0;
BA_ "GenSigSNA" SG_ 1001 DAS_hazardLightRequest "3";
BA_ "Confidence" SG_ 1001 DAS_wiperSpeed 0;
BA_ "Confidence" SG_ 1001 DAS_turnIndicatorRequest 0;
BA_ "Confidence" SG_ 1001 DAS_highLowBeamDecision 0;
BA_ "GenSigSNA" SG_ 1001 DAS_highLowBeamDecision "3";
BA_ "Confidence" SG_ 1001 DAS_heaterRequest 0;
BA_ "GenSigSNA" SG_ 1001 DAS_heaterRequest "0";
BA_ "Confidence" SG_ 1001 DAS_highLowBeamOffReason 0;
BA_ "GenSigSNA" SG_ 1001 DAS_highLowBeamOffReason "5";
BA_ "Confidence" SG_ 1001 DAS_forwardCamHeaterDutyCycle 0;
BA_ "Confidence" SG_ 1001 DAS_dynamicBrakeLightRequest 0;
BA_ "Confidence" SG_ 1001 DAS_radarHeaterRequest 0;
BA_ "Confidence" SG_ 1001 DAS_ahlbOverride 0;
BA_ "Confidence" SG_ 1001 DAS_mirrorFoldRequest 0;
BA_ "GenSigSNA" SG_ 1001 DAS_mirrorFoldRequest "3";
BA_ "Confidence" SG_ 1001 DAS_wiperWashRequest 0;
BA_ "Confidence" SG_ 1001 DAS_ulcConfirmationRequestActive 0;
BA_ "Confidence" SG_ 1001 DAS_overrideWiperSetting 0;
BA_ "Confidence" SG_ 1001 DAS_autoWiperState 0;
BA_ "GenSigSNA" SG_ 1001 DAS_autoWiperState "5";
BA_ "Confidence" SG_ 1001 DAS_turnIndicatorRequestReason 0;
BA_ "Confidence" SG_ 1001 DAS_forwardRadarPowerRequest 0;
BA_ "Confidence" SG_ 1001 DAS_driverDomeLightRequest 0;
BA_ "Confidence" SG_ 1001 DAS_drivePowerStateRequest 0;
BA_ "Confidence" SG_ 1001 DAS_enableIcrDataCollection 0;
BA_ "Confidence" SG_ 1001 DAS_rPillarCamHeaterDutyCycle 0;
BA_ "Confidence" SG_ 1001 DAS_adaptiveHighBeamIsFaulted 0;
BA_ "Confidence" SG_ 1001 DAS_restrictDoorReleaseLeft 0;
BA_ "Confidence" SG_ 1001 DAS_restrictDoorReleaseRight 0;
BA_ "Confidence" SG_ 1001 DAS_bodyControlsCounter 0;
BA_ "Confidence" SG_ 1001 DAS_bodyControlsChecksum 0;
VAL_ 798 CP_matrixIndex 3 "AlertMatrix3" 2 "AlertMatrix2" 1 "AlertMatrix1" 0 "AlertMatrix0" ;
VAL_ 317 CP_powerTransferStatus 6 "CP_POWER_TRANSFER_FAULTED" 5 "CP_POWER_TRANSFER_ENABLED" 4 "CP_EVSE_TEST_PASSED" 3 "CP_EXT_EVSE_TEST_ACTIVE" 2 "CP_POWER_TRANSFER_STANDBY" 1 "CP_POWER_TRANSFER_CONNECTED" 0 "CP_POWER_TRANSFER_INACTIVE" ;
VAL_ 317 CP_powerTransferShutdownRequest 3 "EMERGENCY_SHUTDOWN_REQUESTED" 2 "ESCALATED_SHUTDOWN_REQUESTED" 1 "GRACEFUL_SHUTDOWN_REQUESTED" 0 "NO_SHUTDOWN_REQUESTED" ;
VAL_ 317 CP_evseAcControlMode 3 "AC_CTRL_MODE_GRID_FOLLOW" 2 "AC_CTRL_MODE_GRID_FORM" 1 "AC_CTRL_MODE_CHARGE_ONLY" 0 "AC_CTRL_MODE_NONE" ;
VAL_ 317 CP_evseChargeType 2 "AC_CHARGER_PRESENT" 1 "DC_CHARGER_PRESENT" 0 "NO_CHARGER_PRESENT" ;
VAL_ 317 CP_chgLimitMode 6 "CP_CHG_LIMIT_NUM" 5 "CP_CHG_LIMIT_ADAPTER_HW" 4 "CP_CHG_LIMIT_DEBUG_OVERRIDE" 3 "CP_CHG_LIMIT_ADAPTER_FOLDBACK" 2 "CP_CHG_LIMIT_THERMAL_FOLDBACK" 1 "CP_CHG_LIMIT_CABLE_UNSECURED" 0 "CP_CHG_LIMIT_HW" ;
VAL_ 669 CP_evseDeratingReason 31 "EVSE_DERATING_INVALID" 2 "EVSE_DERATING_POST_SYSTEM_FAULT" 1 "EVSE_DERATING_CABLE_TEMP_FOLDBACK" 0 "EVSE_DERATING_NONE" ;
VAL_ 541 CP_proximity 3 "CHG_PROXIMITY_LATCHED" 2 "CHG_PROXIMITY_UNLATCHED" 1 "CHG_PROXIMITY_DISCONNECTED" 0 "CHG_PROXIMITY_SNA" ;
VAL_ 541 CP_pilot 7 "CHG_PILOT_SNA" 6 "CHG_PILOT_UNUSED_6" 5 "CHG_PILOT_INVALID" 4 "CHG_PILOT_IDLE" 3 "CHG_PILOT_FAST_CHARGE" 2 "CHG_PILOT_LINE_CHARGE" 1 "CHG_PILOT_FAULTED" 0 "CHG_PILOT_NONE" ;
VAL_ 541 CP_cableType 5 "CHG_CABLE_TYPE_SNA" 4 "CHG_CABLE_TYPE_MCS" 3 "CHG_CABLE_TYPE_GB_DC" 2 "CHG_CABLE_TYPE_GB_AC" 1 "CHG_CABLE_TYPE_SAE" 0 "CHG_CABLE_TYPE_IEC" ;
VAL_ 541 CP_iecPilotState 9 "IEC_PILOT_SNA" 8 "IEC_PILOT_NUM" 7 "IEC_PILOT_F" 6 "IEC_PILOT_E" 5 "IEC_PILOT_C3" 4 "IEC_PILOT_C2" 3 "IEC_PILOT_C1" 2 "IEC_PILOT_B3" 1 "IEC_PILOT_B2" 0 "IEC_PILOT_B1" ;
VAL_ 541 CP_teslaSwcanState 8 "TESLA_SWCAN_V2L_ESTABLISHED" 7 "TESLA_SWCAN_V2L_RECEIVE" 6 "TESLA_SWCAN_OFFBOARD_UPDATE_IN_PROGRESS" 5 "TESLA_SWCAN_GO_TO_SLEEP" 4 "TESLA_SWCAN_FAULT" 3 "TESLA_SWCAN_ESTABLISHED" 2 "TESLA_SWCAN_RECEIVE" 1 "TESLA_SWCAN_ACCEPT" 0 "TESLA_SWCAN_INACTIVE" ;
VAL_ 541 CP_evseChargeType_UI 2 "AC_CHARGER_PRESENT" 1 "DC_CHARGER_PRESENT" 0 "NO_CHARGER_PRESENT" ;
VAL_ 541 CP_gbState 15 "GBDC_TESTER_PRESENT" 14 "GBDC_FAULTED" 13 "GBDC_RETRY_CHARGE" 12 "GBDC_ERROR_HANDLING" 11 "GBDC_END_OF_CHARGE" 10 "GBDC_CHARGE_DISABLING" 9 "GBDC_STOP_CHARGE_REQUESTED" 8 "GBDC_CHARGING" 7 "GBDC_READY_TO_CHARGE" 6 "GBDC_VEH_PACK_PRECHARGE" 5 "GBDC_CHARGE_PARAM_CONFIG" 4 "GBDC_RECOGNITION" 3 "GBDC_HANDSHAKING_EXT_ISO" 2 "GBDC_COMMS_RECEIVED" 1 "GBDC_WAIT_FOR_COMMS" 0 "GBDC_INACTIVE" ;
VAL_ 541 CP_gbdcStopChargeReason 8 "GBDC_PARAM_MISMATCH" 7 "GBDC_SUPERCHARGER_COMMS_TIMEOUT" 6 "GBDC_LIVE_DISCONNECT" 5 "GBDC_EVSE_CRITICAL_FAULT" 4 "GBDC_EVSE_FAULT" 3 "GBDC_COMMS_TIMEOUT" 2 "GBDC_EVSE_REQUESTED" 1 "GBDC_VEH_REQUESTED" 0 "GBDC_STOP_REASON_NONE" ;
VAL_ 541 CP_gbdcFailureReason 3 "GBDC_CRITICAL_FAILURE" 2 "GBDC_SHUTDOWN_FAILURE" 1 "GBDC_ATTEMPTS_EXPIRED" 0 "GBDC_FAILURE_NONE" ;
VAL_ 541 CP_acChargeState 6 "AC_CHARGE_FAULT" 5 "AC_CHARGE_VEH_SHUTDOWN" 4 "AC_CHARGE_ONBOARD_CHARGER_SHUTDOWN" 3 "AC_CHARGE_ENABLED" 2 "AC_CHARGE_STANDBY" 1 "AC_CHARGE_CONNECTED_CHARGE_BLOCKED" 0 "AC_CHARGE_INACTIVE" ;
VAL_ 541 CP_acChargeType 3 "AC_CHARGE_TYPE_COUNT" 2 "AC_CHARGE_CCS" 1 "AC_CHARGE_SWCAN" 0 "AC_CHARGE_LEGACY" ;
VAL_ 541 CP_teslaDcState 10 "TESLA_DC_FAULT" 9 "TESLA_DC_EMERGENCY_SHUTDOWN" 8 "TESLA_DC_VEH_SHUTDOWN" 7 "TESLA_DC_EVSE_SHUTDOWN" 6 "TESLA_DC_ENABLED" 5 "TESLA_DC_EXT_PRECHARGE_ACTIVE" 4 "TESLA_DC_EXT_TEST_ACTIVE" 3 "TESLA_DC_EXT_TESTS_ENABLED" 2 "TESLA_DC_STANDBY" 1 "TESLA_DC_CONNECTED_CHARGE_BLOCKED" 0 "TESLA_DC_INACTIVE" ;
VAL_ 733 CP_gridFormFrequencyRequest 4095 "SNA" ;
VAL_ 733 CP_gridFormL1NVoltageRequest 255 "SNA" ;
VAL_ 733 CP_gridFormGroundType 4 "CP_L1_L2_L3_MIDPOINT_GROUNDED_VEH_SIDE" 3 "CP_N_GROUNDED_EVSE_SIDE" 2 "CP_N_L1_MIDPOINT_GROUNDED_EVSE_SIDE" 1 "CP_NO_GROUNDING_EVSE_SIDE" 0 "GROUND_TYPE_SNA" ;
VAL_ 733 CP_gridFormGridType 4 "CP_P_L1L2_N_L3N_DC" 3 "CP_L1_L2_L3_THREE_PHASE" 2 "CP_N_L1_SPLIT_PHASE" 1 "CP_N_L1_SINGLE_PHASE" 0 "GRID_TYPE_SNA" ;
VAL_ 733 CP_powershareType 4 "POWERSHARE_TYPE_EPTO" 3 "POWERSHARE_TYPE_GRID" 2 "POWERSHARE_TYPE_HOME" 1 "POWERSHARE_TYPE_LOAD" 0 "POWERSHARE_TYPE_NONE" ;
VAL_ 733 CP_userPowershareStatus 5 "POWERSHARE_STOPPED" 4 "POWERSHARE_ENABLED_RECONNECTING_SOON" 3 "POWERSHARE_ENABLED" 2 "POWERSHARE_INITIALIZING" 1 "POWERSHARE_HANDSHAKING" 0 "POWERSHARE_INACTIVE" ;
VAL_ 733 CP_powershareStoppedReason 8 "POWERSHARE_STOP_REASON_AUTHENTICATION_FAILED" 7 "POWERSHARE_STOP_REASON_OFFBOARD_UPDATE" 6 "POWERSHARE_STOP_REASON_NOT_AUTHORIZED" 5 "POWERSHARE_STOP_REASON_GRID_RECONNECTING" 4 "POWERSHARE_STOP_REASON_USER" 3 "POWERSHARE_STOP_REASON_SOC_TOO_LOW" 2 "POWERSHARE_STOP_REASON_RETRY" 1 "POWERSHARE_STOP_REASON_FAULT" 0 "POWERSHARE_STOP_REASON_NONE" ;
VAL_ 1342 CP_infoIndex 255 "END" 31 "SUBCOMPONENT_GITHASH" 30 "PACKAGE_SN_8_14" 29 "PACKAGE_SN_1_7" 27 "PACKAGE_PN_15_20" 26 "PACKAGE_PN_8_14" 25 "PACKAGE_PN_1_7" 23 "SUBCOMPONENT2" 22 "VARIANTCRC" 20 "UDS_PROTOCOL_BOOTCRC" 19 "VERSION_DEPRECATED" 18 "BOOTLOADER_GITHASH" 17 "APP_GITHASH" 16 "SUBCOMPONENT" 15 "BOOTLOADER_CRC" 14 "BOOTLOADER_SVN" 13 "APP_CRC" 11 "PCBAID_ASSYID_USAGEID" 10 "BUILD_HWID_COMPONENTID" 9 "DEPRECATED_9" 8 "DEPRECATED_8" 7 "DEPRECATED_7" 6 "DEPRECATED_6" 5 "DEPRECATED_5" 4 "DEPRECATED_4" 3 "DEPRECATED_3" 2 "DEPRECATED_2" 1 "DEPRECATED_1" 0 "DEPRECATED_0" ;
VAL_ 1342 CP_buildType 4 "INFO_MFG_BUILD" 3 "INFO_TRACEABLE_CI_BUILD" 2 "INFO_LOCAL_BUILD" 1 "INFO_PLATFORM_BUILD" 0 "INFO_UNKNOWN_BUILD" ;
VAL_ 1885 CP_loggingFastSelect 6 "6" 5 "5" 4 "4" 3 "3" 2 "2" 1 "1" 0 "0" ;
VAL_ 1885 CP_chargeCablePresent 1 "CABLE_PRESENT" 0 "CABLE_NOT_PRESENT" ;
VAL_ 1885 CP_UHF_controlState 10 "CP_UHF_FAULT" 9 "CP_UHF_SLEEP" 8 "CP_UHF_HANDLE_FOUND" 7 "CP_UHF_READ_RXFIFO" 6 "CP_UHF_CHECK_RX" 5 "CP_UHF_RX" 4 "CP_UHF_PREPARE_RX" 3 "CP_UHF_CALIBRATE" 2 "CP_UHF_IDLE" 1 "CP_UHF_CONFIG" 0 "CP_UHF_INIT" ;
VAL_ 1885 CP_doorOpenRequest 8 "CPD_OPEN_REQ_NUM" 7 "CPD_OPEN_REQ_CABLE_RECONNECTED" 6 "CPD_OPEN_REQ_VCFRONT" 5 "CPD_OPEN_REQ_CLOSING_FAILED" 4 "CPD_OPEN_REQ_PUSH_TO_OPEN" 3 "CPD_OPEN_REQ_UHF" 2 "CPD_OPEN_REQ_SEC" 1 "CPD_OPEN_REQ_UI" 0 "CPD_OPEN_REQ_NONE" ;
VAL_ 1885 CP_doorOpenEndOfDriveReason 7 "CP_STOP_DRIVE_REASON_OVERCURRENT" 6 "CP_STOP_DRIVE_REASON_REQ_OVERRIDE" 5 "CP_STOP_DRIVE_REASON_ABSOLUTE_TIMEOUT" 4 "CP_STOP_DRIVE_REASON_MAX_TARGET_V" 3 "CP_STOP_DRIVE_REASON_REACHED_STOP" 2 "CP_STOP_DRIVE_REASON_STOPPED_MOVING_TIMEOUT" 1 "CP_STOP_DRIVE_REASON_STALLED" 0 "CP_STOP_DRIVE_REASON_NONE" ;
VAL_ 1885 CP_doorCloseEndOfDriveReason 7 "CP_STOP_DRIVE_REASON_OVERCURRENT" 6 "CP_STOP_DRIVE_REASON_REQ_OVERRIDE" 5 "CP_STOP_DRIVE_REASON_ABSOLUTE_TIMEOUT" 4 "CP_STOP_DRIVE_REASON_MAX_TARGET_V" 3 "CP_STOP_DRIVE_REASON_REACHED_STOP" 2 "CP_STOP_DRIVE_REASON_STOPPED_MOVING_TIMEOUT" 1 "CP_STOP_DRIVE_REASON_STALLED" 0 "CP_STOP_DRIVE_REASON_NONE" ;
VAL_ 1885 CP_doorCloseRequest 16 "CPD_CLOSE_REQ_NUM" 15 "CPD_CLOSE_REQ_COVER_OPEN" 14 "CPD_CLOSE_REQ_VCFRONT" 13 "CPD_CLOSE_REQ_OPEN_ON_WAKE" 12 "CPD_CLOSE_REQ_SENSOR_COMMS_RECOVERED" 11 "CPD_CLOSE_REQ_SENSOR_MISMATCH" 10 "CPD_CLOSE_REQ_INITIAL_CINCH" 9 "CPD_CLOSE_REQ_OPENED_IN_DRIVE_STATE" 8 "CPD_CLOSE_REQ_ENTER_DRIVE" 7 "CPD_CLOSE_REQ_FAULT_LINE" 6 "CPD_CLOSE_REQ_CAR_WASH" 5 "CPD_CLOSE_REQ_PUSH_TO_CLOSE" 4 "CPD_CLOSE_REQ_SEC" 3 "CPD_CLOSE_REQ_UI" 2 "CPD_CLOSE_REQ_DOOR_OPEN_TIMEOUT" 1 "CPD_CLOSE_REQ_CABLE_UNPLUGGED" 0 "CPD_CLOSE_REQ_NONE" ;
VAL_ 1885 CP_latchDisengagingStopReason 7 "CP_STOP_DRIVE_REASON_OVERCURRENT" 6 "CP_STOP_DRIVE_REASON_REQ_OVERRIDE" 5 "CP_STOP_DRIVE_REASON_ABSOLUTE_TIMEOUT" 4 "CP_STOP_DRIVE_REASON_MAX_TARGET_V" 3 "CP_STOP_DRIVE_REASON_REACHED_STOP" 2 "CP_STOP_DRIVE_REASON_STOPPED_MOVING_TIMEOUT" 1 "CP_STOP_DRIVE_REASON_STALLED" 0 "CP_STOP_DRIVE_REASON_NONE" ;
VAL_ 1885 CP_latchEngagingStopReason 7 "CP_STOP_DRIVE_REASON_OVERCURRENT" 6 "CP_STOP_DRIVE_REASON_REQ_OVERRIDE" 5 "CP_STOP_DRIVE_REASON_ABSOLUTE_TIMEOUT" 4 "CP_STOP_DRIVE_REASON_MAX_TARGET_V" 3 "CP_STOP_DRIVE_REASON_REACHED_STOP" 2 "CP_STOP_DRIVE_REASON_STOPPED_MOVING_TIMEOUT" 1 "CP_STOP_DRIVE_REASON_STALLED" 0 "CP_STOP_DRIVE_REASON_NONE" ;
VAL_ 1885 CP_doorIdDetectionState 2 "DOOR_ID_VALID" 1 "DOOR_ID_INVALID" 0 "DOOR_ID_UNKNOWN_SNA" ;
VAL_ 1885 CP_doorIdDetectedBin 3 "DOOR_ID_BIN_OPAL" 2 "DOOR_ID_BIN_HMC" 1 "DOOR_ID_BIN_NMB" 0 "DOOR_ID_BIN_UNKNOWN" ;
VAL_ 989 CP_loggingSlowSelect 8 "8" 7 "7" 6 "6" 5 "5" 4 "4" 3 "3" 2 "2" 1 "1" 0 "0" ;
VAL_ 989 CP_inlet1HarnessIdState 2 "HARNESS_PEDIGREE_VALID" 1 "HARNESS_PEDIGREE_INVALID" 0 "HARNESS_PEDIGREE_UNKNOWN_SNA" ;
VAL_ 989 CP_inlet2HarnessIdState 2 "HARNESS_PEDIGREE_VALID" 1 "HARNESS_PEDIGREE_INVALID" 0 "HARNESS_PEDIGREE_UNKNOWN_SNA" ;
VAL_ 989 CP_inletHeaterState 3 "INLET_HEATER_FAULTED" 2 "INLET_HEATER_ENABLED_LOWTEMP" 1 "INLET_HEATER_ENABLED_HIGHTEMP" 0 "INLET_HEATER_DISABLED" ;
VAL_ 989 CP_doorOpenLimiterMaxRequestType 8 "CPD_OPEN_REQ_NUM" 7 "CPD_OPEN_REQ_CABLE_RECONNECTED" 6 "CPD_OPEN_REQ_VCFRONT" 5 "CPD_OPEN_REQ_CLOSING_FAILED" 4 "CPD_OPEN_REQ_PUSH_TO_OPEN" 3 "CPD_OPEN_REQ_UHF" 2 "CPD_OPEN_REQ_SEC" 1 "CPD_OPEN_REQ_UI" 0 "CPD_OPEN_REQ_NONE" ;
VAL_ 989 CP_doorCloseLimiterMaxRequestTyp 16 "CPD_CLOSE_REQ_NUM" 15 "CPD_CLOSE_REQ_COVER_OPEN" 14 "CPD_CLOSE_REQ_VCFRONT" 13 "CPD_CLOSE_REQ_OPEN_ON_WAKE" 12 "CPD_CLOSE_REQ_SENSOR_COMMS_RECOVERED" 11 "CPD_CLOSE_REQ_SENSOR_MISMATCH" 10 "CPD_CLOSE_REQ_INITIAL_CINCH" 9 "CPD_CLOSE_REQ_OPENED_IN_DRIVE_STATE" 8 "CPD_CLOSE_REQ_ENTER_DRIVE" 7 "CPD_CLOSE_REQ_FAULT_LINE" 6 "CPD_CLOSE_REQ_CAR_WASH" 5 "CPD_CLOSE_REQ_PUSH_TO_CLOSE" 4 "CPD_CLOSE_REQ_SEC" 3 "CPD_CLOSE_REQ_UI" 2 "CPD_CLOSE_REQ_DOOR_OPEN_TIMEOUT" 1 "CPD_CLOSE_REQ_CABLE_UNPLUGGED" 0 "CPD_CLOSE_REQ_NONE" ;
VAL_ 605 CP_type 3 "CP_TYPE_IEC_CCS" 2 "CP_TYPE_GB" 1 "CP_TYPE_EURO_IEC" 0 "CP_TYPE_US_TESLA" ;
VAL_ 605 CP_latchState 3 "CP_LATCH_BLOCKING" 2 "CP_LATCH_ENGAGED" 1 "CP_LATCH_DISENGAGED" 0 "CP_LATCH_SNA" ;
VAL_ 605 CP_doorControlState 6 "CP_doorSenseClosed" 5 "CP_doorClosing" 4 "CP_doorSenseOpen" 3 "CP_doorOpening" 2 "CP_doorOpenRequested" 1 "CP_doorIdle" 0 "CP_doorInit" ;
VAL_ 605 CP_chargeCableState 2 "CHARGE_CABLE_CONNECTED" 1 "CHARGE_CABLE_NOT_CONNECTED" 0 "CHARGE_CABLE_UNKNOWN_SNA" ;
VAL_ 605 CP_latchControlState 5 "CP_latchEngaging" 4 "CP_latchDisengaged" 3 "CP_latchDisengaging" 2 "CP_latchDisengageRequested" 1 "CP_latchIdle" 0 "CP_latchInit" ;
VAL_ 605 CP_ledColor 13 "CP_LEDS_FLASHING_WHITE" 12 "CP_LEDS_FADING_OUT" 11 "CP_LEDS_FLASHING_PURPLE" 10 "CP_LEDS_FLASHING_BLUE" 9 "CP_LEDS_DEBUG" 8 "CP_LEDS_RAVE" 7 "CP_LEDS_AMBER" 6 "CP_LEDS_FLASHING_AMBER" 5 "CP_LEDS_FLASHING_GREEN" 4 "CP_LEDS_WHITE" 3 "CP_LEDS_BLUE" 2 "CP_LEDS_GREEN" 1 "CP_LEDS_RED" 0 "CP_LEDS_OFF" ;
VAL_ 605 CP_faultLineSensed 1 "FAULT_LINE_SET" 0 "FAULT_LINE_CLEARED" ;
VAL_ 605 CP_doorPresenceState 7 "CP_DOOR_PRESENCE_STATE_FAULT" 6 "CP_DOOR_PRESENCE_STATE_OFF_CHARGE" 5 "CP_DOOR_PRESENCE_STATE_OFF_DRIVE" 4 "CP_DOOR_PRESENCE_STATE_NOT_PRESENT" 3 "CP_DOOR_PRESENCE_STATE_PRESENT" 2 "CP_DOOR_PRESENCE_STATE_INIT_FROM_DRIVE" 1 "CP_DOOR_PRESENCE_STATE_INIT_FROM_CHARGE" 0 "CP_DOOR_PRESENCE_STATE_INIT" ;
VAL_ 605 CP_inductiveSensorState 7 "CP_INDUCTIVE_SENSOR_CONFIG" 6 "CP_INDUCTIVE_SENSOR_RESET" 5 "CP_INDUCTIVE_SENSOR_FAULT" 4 "CP_INDUCTIVE_SENSOR_WAIT_FOR_INIT" 3 "CP_INDUCTIVE_SENSOR_PAUSE" 2 "CP_INDUCTIVE_SENSOR_SHUTDOWN" 1 "CP_INDUCTIVE_SENSOR_POLL" 0 "CP_INDUCTIVE_SENSOR_INIT" ;
VAL_ 605 CP_coldWeatherMode 1 "CP_COLD_WEATHER_LATCH_MITIGATION" 0 "CP_COLD_WEATHER_NONE" ;
VAL_ 605 CP_inletHeaterUiState 4 "CP_HEATER_FAULTED" 3 "CP_HEATER_ENABLED" 2 "CP_HEATER_AVAILABLE" 1 "CP_HEATER_NOT_AVAILABLE" 0 "CP_HEATER_NOT_SUPPORTED" ;
VAL_ 605 CP_userEvseModelType 10 "EVSE_MODEL_V2L_ADAPTER" 9 "EVSE_MODEL_URBAN_CHARGER_V2" 8 "EVSE_MODEL_V2H_UWC" 7 "EVSE_MODEL_V2L_UMC3" 6 "EVSE_MODEL_TESLA_WC" 5 "EVSE_MODEL_TESLA_UMC" 4 "EVSE_MODEL_SUPERCHARGER_V4" 3 "EVSE_MODEL_SUPERCHARGER" 2 "EVSE_MODEL_GENERIC_FAST_CHARGER" 1 "EVSE_MODEL_GENERIC_CHARGER" 0 "EVSE_MODEL_NO_CHARGER" ;
VAL_ 605 CP_evseGridFormHardwareType 15 "EVSE_GRID_FORM_HARDWARE_SNA" 1 "EVSE_GRID_FORM_HARDWARE_V2LA" 0 "EVSE_GRID_FORM_HARDWARE_UMC3" ;
VAL_ 605 CP_AuthManagerState 8 "CP_AUTH_MANAGER_STATUS_ERROR" 7 "CP_AUTH_MANAGER_STATUS_SUCCESS" 6 "CP_AUTH_MANAGER_STATUS_VERIFYING_SIGNATURE" 5 "CP_AUTH_MANAGER_STATUS_WAITING_FOR_SIGNATURE" 4 "CP_AUTH_MANAGER_STATUS_WAITING_FOR_CHALLENGE" 3 "CP_AUTH_MANAGER_STATUS_VERIFYING_CERTIFICATE" 2 "CP_AUTH_MANAGER_STATUS_WAITING_FOR_CERTIFICATE" 1 "CP_AUTH_MANAGER_STATUS_IDLE" 0 "CP_AUTH_MANAGER_STATUS_INIT" ;
VAL_ 893 CP_thermalStatusSelect 1 "1" 0 "0" ;
VAL_ 893 CP_pinTemp4Velocity 511 "SNA" ;
VAL_ 1001 DAS_headlightRequest 3 "DAS_HEADLIGHT_REQUEST_INVALID" 2 "DAS_HEADLIGHT_REQUEST_TAIL_LIGHTS_ONLY" 1 "DAS_HEADLIGHT_REQUEST_ON" 0 "DAS_HEADLIGHT_REQUEST_OFF" ;
VAL_ 1001 DAS_hazardLightRequest 3 "DAS_REQUEST_HAZARDS_SNA" 2 "DAS_REQUEST_HAZARDS_ON_FAST" 1 "DAS_REQUEST_HAZARDS_ON" 0 "DAS_REQUEST_HAZARDS_OFF" ;
VAL_ 1001 DAS_wiperSpeed 15 "DAS_WIPER_SPEED_INVALID" 14 "DAS_WIPER_SPEED_14" 13 "DAS_WIPER_SPEED_13" 12 "DAS_WIPER_SPEED_12" 11 "DAS_WIPER_SPEED_11" 10 "DAS_WIPER_SPEED_10" 9 "DAS_WIPER_SPEED_9" 8 "DAS_WIPER_SPEED_8" 7 "DAS_WIPER_SPEED_7" 6 "DAS_WIPER_SPEED_6" 5 "DAS_WIPER_SPEED_5" 4 "DAS_WIPER_SPEED_4" 3 "DAS_WIPER_SPEED_3" 2 "DAS_WIPER_SPEED_2" 1 "DAS_WIPER_SPEED_1" 0 "DAS_WIPER_SPEED_OFF" ;
VAL_ 1001 DAS_turnIndicatorRequest 4 "DAS_TURN_INDICATOR_DEFER" 3 "DAS_TURN_INDICATOR_CANCEL" 2 "DAS_TURN_INDICATOR_RIGHT" 1 "DAS_TURN_INDICATOR_LEFT" 0 "DAS_TURN_INDICATOR_NONE" ;
VAL_ 1001 DAS_highLowBeamDecision 3 "DAS_HIGH_BEAM_SNA" 2 "DAS_HIGH_BEAM_ON" 1 "DAS_HIGH_BEAM_OFF" 0 "DAS_HIGH_BEAM_UNDECIDED" ;
VAL_ 1001 DAS_heaterRequest 2 "DAS_HEATER_ON" 1 "DAS_HEATER_OFF" 0 "DAS_HEATER_SNA" ;
VAL_ 1001 DAS_highLowBeamOffReason 5 "HIGH_BEAM_OFF_REASON_SNA" 4 "HIGH_BEAM_OFF_REASON_HEAD_LIGHT" 3 "HIGH_BEAM_OFF_REASON_AMBIENT_LIGHT" 2 "HIGH_BEAM_OFF_REASON_MOVING_RADAR_TARGET" 1 "HIGH_BEAM_OFF_REASON_MOVING_VISION_TARGET" 0 "HIGH_BEAM_ON" ;
VAL_ 1001 DAS_mirrorFoldRequest 3 "DAS_MIRROR_REQUEST_SNA" 2 "DAS_MIRROR_REQUEST_UNFOLD" 1 "DAS_MIRROR_REQUEST_FOLD" 0 "DAS_MIRROR_REQUEST_NONE" ;
VAL_ 1001 DAS_autoWiperState 5 "DAS_AUTO_WIPER_STATE_SNA" 4 "DAS_AUTO_WIPER_STATE_FAST_CONTINUOUS" 3 "DAS_AUTO_WIPER_STATE_SLOW_CONTINUOUS" 2 "DAS_AUTO_WIPER_STATE_FAST_INTERMITTENT" 1 "DAS_AUTO_WIPER_STATE_SLOW_INTERMITTENT" 0 "DAS_AUTO_WIPER_STATE_OFF" ;
VAL_ 1001 DAS_turnIndicatorRequestReason 24 "DAS_ACTIVE_SIMULTANEOUS_LANE_CHANGE_AVOIDANCE" 23 "DAS_ACTIVE_INFEASIBLE_KINEMATICS_LANE_CHANGE" 22 "DAS_ACTIVE_STAY_OUT_OF_RIGHTMOST_LANE_LANE_CHANGE" 21 "DAS_ACTIVE_AWAY_FROM_MERGE_LANE_CHANGE" 20 "DAS_ACTIVE_EXIT_RIGHT_LANE_LANE_CHANGE" 19 "DAS_ACTIVE_EXIT_PASSING_LANE_LANE_CHANGE" 18 "DAS_ACTIVE_INCORRECT_ROAD_SIDE_LANE_CHANGE" 17 "DAS_ACTIVE_STATIC_OBJECT_LANE_CHANGE" 15 "DAS_CANCEL_MANUAL_BLINKER" 14 "DAS_CANCEL_AUTO_PARK" 13 "DAS_ACTIVE_AUTO_PARK" 12 "DAS_CANCEL_SUMMMON" 11 "DAS_ACTIVE_SUMMMON" 10 "DAS_CANCEL_INTERSECTION" 9 "DAS_ACTIVE_INTERSECTION" 8 "DAS_ACTIVE_COMMANDED_LANE_CHANGE" 7 "DAS_CANCEL_MERGE" 6 "DAS_ACTIVE_MERGE" 5 "DAS_CANCEL_FORK" 4 "DAS_CANCEL_LANE_CHANGE" 3 "DAS_ACTIVE_FORK" 2 "DAS_ACTIVE_SPEED_LANE_CHANGE" 1 "DAS_ACTIVE_NAV_LANE_CHANGE" 0 "DAS_NONE" ;
VAL_ 1001 DAS_restrictDoorReleaseLeft 1 "RESTRICT_DOOR_RELEASE_ACTIVE" 0 "RESTRICT_DOOR_RELEASE_INACTIVE" ;
VAL_ 1001 DAS_restrictDoorReleaseRight 1 "RESTRICT_DOOR_RELEASE_ACTIVE" 0 "RESTRICT_DOOR_RELEASE_INACTIVE" ;
